[part 1 of 2: package /STELLANTIS/EPT/ASWCs]
AUTOSAR XML (schema 4-2-2)
package /STELLANTIS/EPT/ASWCs
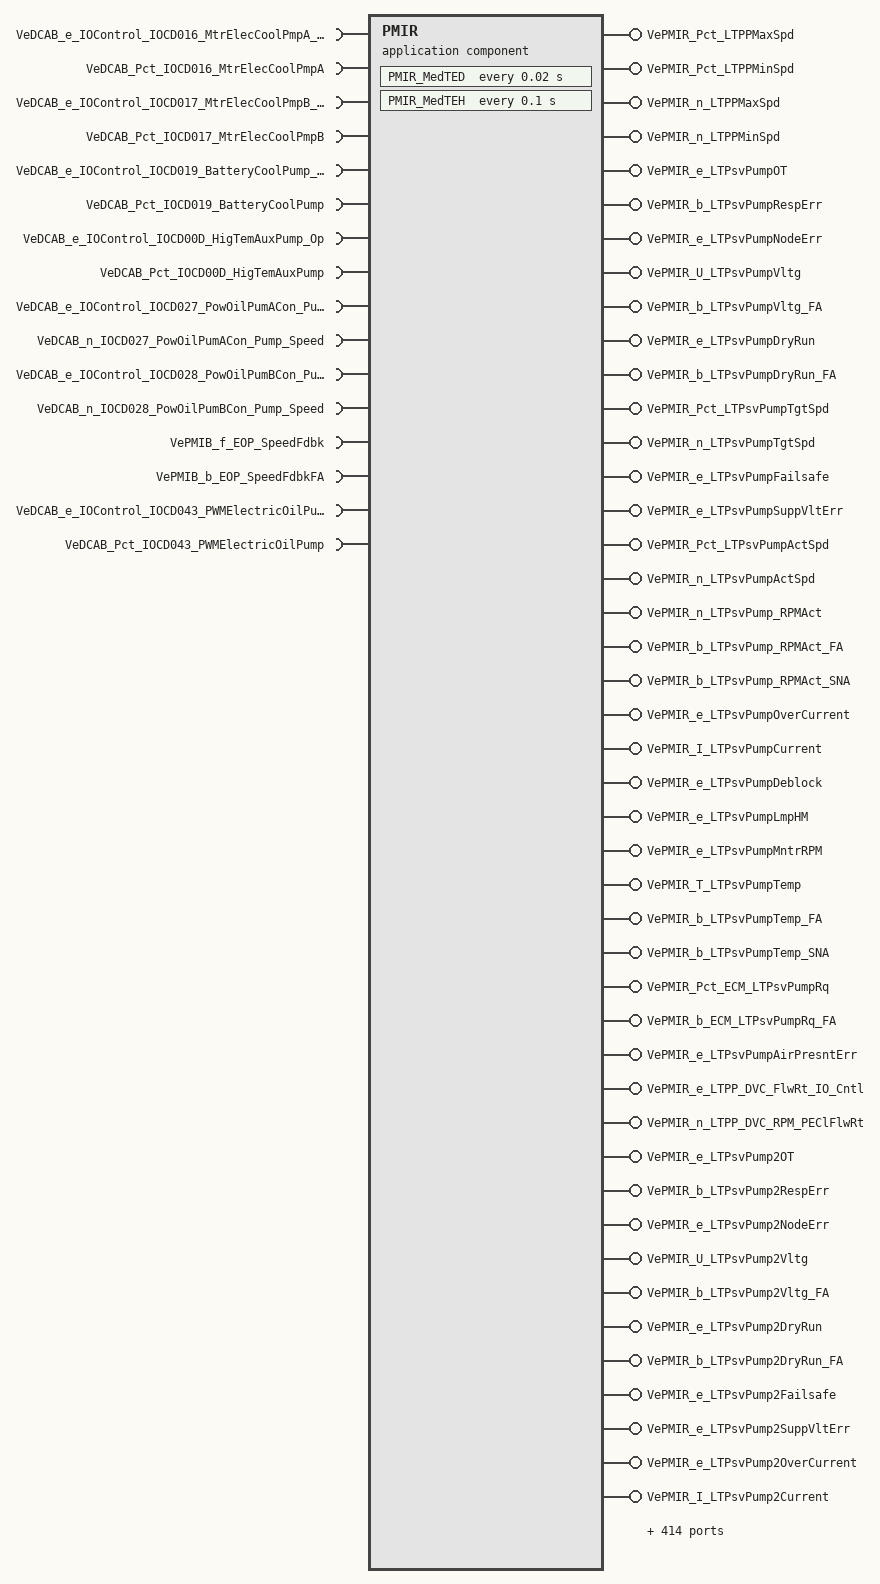
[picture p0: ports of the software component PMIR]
  application sw component type PMIR
    16 x require port:
      VeDCAB_e_IOControl_IOCD016_MtrElecCoolPmpA_Op: nonqueued-receiver-com-spec{data-element=Value, init-value=CeDCAB_e_IO_NOP}, required-interface=VeDCAB_e_IOControl_IOCD016_MtrElecCoolPmpA_Op
      VeDCAB_Pct_IOCD016_MtrElecCoolPmpA: nonqueued-receiver-com-spec{data-element=Value, init-value=0}, required-interface=VeDCAB_Pct_IOCD016_MtrElecCoolPmpA
      VeDCAB_e_IOControl_IOCD017_MtrElecCoolPmpB_Op: nonqueued-receiver-com-spec{data-element=Value, init-value=CeDCAB_e_IO_NOP}, required-interface=VeDCAB_e_IOControl_IOCD017_MtrElecCoolPmpB_Op
      VeDCAB_Pct_IOCD017_MtrElecCoolPmpB: nonqueued-receiver-com-spec{data-element=Value, init-value=0}, required-interface=VeDCAB_Pct_IOCD017_MtrElecCoolPmpB
      VeDCAB_e_IOControl_IOCD019_BatteryCoolPump_Op: nonqueued-receiver-com-spec{data-element=Value, init-value=CeDCAB_e_IO_NOP}, required-interface=VeDCAB_e_IOControl_IOCD019_BatteryCoolPump_Op
      VeDCAB_Pct_IOCD019_BatteryCoolPump: nonqueued-receiver-com-spec{data-element=Value, init-value=0}, required-interface=VeDCAB_Pct_IOCD019_BatteryCoolPump
      VeDCAB_e_IOControl_IOCD00D_HigTemAuxPump_Op: nonqueued-receiver-com-spec{data-element=Value, init-value=CeDCAB_e_IO_NOP}, required-interface=VeDCAB_e_IOControl_IOCD00D_HigTemAuxPump_Op
      VeDCAB_Pct_IOCD00D_HigTemAuxPump: nonqueued-receiver-com-spec{data-element=Value, init-value=0}, required-interface=VeDCAB_Pct_IOCD00D_HigTemAuxPump
      VeDCAB_e_IOControl_IOCD027_PowOilPumACon_Pump_Speed_Op: nonqueued-receiver-com-spec{data-element=Value, init-value=CeDCAB_e_IO_NOP}, required-interface=VeDCAB_e_IOControl_IOCD027_PowOilPumACon_Pump_Speed_Op
      VeDCAB_n_IOCD027_PowOilPumACon_Pump_Speed: nonqueued-receiver-com-spec{data-element=Value, init-value=0}, required-interface=VeDCAB_n_IOCD027_PowOilPumACon_Pump_Speed
      VeDCAB_e_IOControl_IOCD028_PowOilPumBCon_Pump_Speed_Op: nonqueued-receiver-com-spec{data-element=Value, init-value=CeDCAB_e_IO_NOP}, required-interface=VeDCAB_e_IOControl_IOCD028_PowOilPumBCon_Pump_Speed_Op
      VeDCAB_n_IOCD028_PowOilPumBCon_Pump_Speed: nonqueued-receiver-com-spec{data-element=Value, init-value=0}, required-interface=VeDCAB_n_IOCD028_PowOilPumBCon_Pump_Speed
      VePMIB_f_EOP_SpeedFdbk: nonqueued-receiver-com-spec{data-element=Value, init-value=0}, required-interface=VePMIB_f_EOP_SpeedFdbk
      VePMIB_b_EOP_SpeedFdbkFA: nonqueued-receiver-com-spec{data-element=Value, init-value=0}, required-interface=VePMIB_b_EOP_SpeedFdbkFA
      VeDCAB_e_IOControl_IOCD043_PWMElectricOilPump_Op: nonqueued-receiver-com-spec{data-element=Value, init-value=CeDCAB_e_IO_NOP}, required-interface=VeDCAB_e_IOControl_IOCD043_PWMElectricOilPump_Op
      VeDCAB_Pct_IOCD043_PWMElectricOilPump: nonqueued-receiver-com-spec{data-element=Value, init-value=0}, required-interface=VeDCAB_Pct_IOCD043_PWMElectricOilPump
    458 x provide port:
      VePMIR_Pct_LTPPMaxSpd: nonqueued-sender-com-spec{data-element=Value, init-value=0}, provided-interface=VePMIR_Pct_LTPPMaxSpd
      VePMIR_Pct_LTPPMinSpd: nonqueued-sender-com-spec{data-element=Value, init-value=0}, provided-interface=VePMIR_Pct_LTPPMinSpd
      VePMIR_n_LTPPMaxSpd: nonqueued-sender-com-spec{data-element=Value, init-value=0}, provided-interface=VePMIR_n_LTPPMaxSpd
      VePMIR_n_LTPPMinSpd: nonqueued-sender-com-spec{data-element=Value, init-value=0}, provided-interface=VePMIR_n_LTPPMinSpd
      VePMIR_e_LTPsvPumpOT: nonqueued-sender-com-spec{data-element=Value, init-value=CePMPR_e_FTSNA_False}, provided-interface=VePMIR_e_LTPsvPumpOT
      VePMIR_b_LTPsvPumpRespErr: nonqueued-sender-com-spec{data-element=Value, init-value=0}, provided-interface=VePMIR_b_LTPsvPumpRespErr
      VePMIR_e_LTPsvPumpNodeErr: nonqueued-sender-com-spec{data-element=Value, init-value=CePMPR_e_NodeError_NoError}, provided-interface=VePMIR_e_LTPsvPumpNodeErr
      VePMIR_U_LTPsvPumpVltg: nonqueued-sender-com-spec{data-element=Value, init-value=0}, provided-interface=VePMIR_U_LTPsvPumpVltg
      VePMIR_b_LTPsvPumpVltg_FA: nonqueued-sender-com-spec{data-element=Value, init-value=0}, provided-interface=VePMIR_b_LTPsvPumpVltg_FA
      VePMIR_e_LTPsvPumpDryRun: nonqueued-sender-com-spec{data-element=Value, init-value=CePMPR_e_FTSNA_False}, provided-interface=VePMIR_e_LTPsvPumpDryRun
      VePMIR_b_LTPsvPumpDryRun_FA: nonqueued-sender-com-spec{data-element=Value, init-value=0}, provided-interface=VePMIR_b_LTPsvPumpDryRun_FA
      VePMIR_Pct_LTPsvPumpTgtSpd: nonqueued-sender-com-spec{data-element=Value, init-value=0}, provided-interface=VePMIR_Pct_LTPsvPumpTgtSpd
      VePMIR_n_LTPsvPumpTgtSpd: nonqueued-sender-com-spec{data-element=Value, init-value=0}, provided-interface=VePMIR_n_LTPsvPumpTgtSpd
      VePMIR_e_LTPsvPumpFailsafe: nonqueued-sender-com-spec{data-element=Value, init-value=CePMPR_e_TFSNA_False}, provided-interface=VePMIR_e_LTPsvPumpFailsafe
      VePMIR_e_LTPsvPumpSuppVltErr: nonqueued-sender-com-spec{data-element=Value, init-value=CePMPR_e_FTSNA_False}, provided-interface=VePMIR_e_LTPsvPumpSuppVltErr
      VePMIR_Pct_LTPsvPumpActSpd: nonqueued-sender-com-spec{data-element=Value, init-value=0}, provided-interface=VePMIR_Pct_LTPsvPumpActSpd
      VePMIR_n_LTPsvPumpActSpd: nonqueued-sender-com-spec{data-element=Value, init-value=0}, provided-interface=VePMIR_n_LTPsvPumpActSpd
      VePMIR_n_LTPsvPump_RPMAct: nonqueued-sender-com-spec{data-element=Value, init-value=0}, provided-interface=VePMIR_n_LTPsvPump_RPMAct
      VePMIR_b_LTPsvPump_RPMAct_FA: nonqueued-sender-com-spec{data-element=Value, init-value=0}, provided-interface=VePMIR_b_LTPsvPump_RPMAct_FA
      VePMIR_b_LTPsvPump_RPMAct_SNA: nonqueued-sender-com-spec{data-element=Value, init-value=0}, provided-interface=VePMIR_b_LTPsvPump_RPMAct_SNA
      VePMIR_e_LTPsvPumpOverCurrent: nonqueued-sender-com-spec{data-element=Value, init-value=CePMPR_e_FTSNA_False}, provided-interface=VePMIR_e_LTPsvPumpOverCurrent
      VePMIR_I_LTPsvPumpCurrent: nonqueued-sender-com-spec{data-element=Value, init-value=0}, provided-interface=VePMIR_I_LTPsvPumpCurrent
      VePMIR_e_LTPsvPumpDeblock: nonqueued-sender-com-spec{data-element=Value, init-value=CePMPR_e_FTSNA_False}, provided-interface=VePMIR_e_LTPsvPumpDeblock
      VePMIR_e_LTPsvPumpLmpHM: nonqueued-sender-com-spec{data-element=Value, init-value=CePMPR_e_FTSNA_False}, provided-interface=VePMIR_e_LTPsvPumpLmpHM
      VePMIR_e_LTPsvPumpMntrRPM: nonqueued-sender-com-spec{data-element=Value, init-value=CePMPR_e_TFSNA_False}, provided-interface=VePMIR_e_LTPsvPumpMntrRPM
      VePMIR_T_LTPsvPumpTemp: nonqueued-sender-com-spec{data-element=Value, init-value=0}, provided-interface=VePMIR_T_LTPsvPumpTemp
      VePMIR_b_LTPsvPumpTemp_FA: nonqueued-sender-com-spec{data-element=Value, init-value=0}, provided-interface=VePMIR_b_LTPsvPumpTemp_FA
      VePMIR_b_LTPsvPumpTemp_SNA: nonqueued-sender-com-spec{data-element=Value, init-value=0}, provided-interface=VePMIR_b_LTPsvPumpTemp_SNA
      VePMIR_Pct_ECM_LTPsvPumpRq: nonqueued-sender-com-spec{data-element=Value, init-value=0}, provided-interface=VePMIR_Pct_ECM_LTPsvPumpRq
      VePMIR_b_ECM_LTPsvPumpRq_FA: nonqueued-sender-com-spec{data-element=Value, init-value=0}, provided-interface=VePMIR_b_ECM_LTPsvPumpRq_FA
      VePMIR_e_LTPsvPumpAirPresntErr: nonqueued-sender-com-spec{data-element=Value, init-value=CePMPR_e_FTSNA_False}, provided-interface=VePMIR_e_LTPsvPumpAirPresntErr
      VePMIR_e_LTPP_DVC_FlwRt_IO_Cntl: nonqueued-sender-com-spec{data-element=Value, init-value=CeTAIR_e_Return_Control_to_ECU}, provided-interface=VePMIR_e_LTPP_DVC_FlwRt_IO_Cntl
      VePMIR_n_LTPP_DVC_RPM_PEClFlwRt: nonqueued-sender-com-spec{data-element=Value, init-value=0}, provided-interface=VePMIR_n_LTPP_DVC_RPM_PEClFlwRt
      VePMIR_e_LTPsvPump2OT: nonqueued-sender-com-spec{data-element=Value, init-value=CePMPR_e_FTSNA_False}, provided-interface=VePMIR_e_LTPsvPump2OT
      VePMIR_b_LTPsvPump2RespErr: nonqueued-sender-com-spec{data-element=Value, init-value=0}, provided-interface=VePMIR_b_LTPsvPump2RespErr
      VePMIR_e_LTPsvPump2NodeErr: nonqueued-sender-com-spec{data-element=Value, init-value=CePMPR_e_NodeError_NoError}, provided-interface=VePMIR_e_LTPsvPump2NodeErr
      VePMIR_U_LTPsvPump2Vltg: nonqueued-sender-com-spec{data-element=Value, init-value=0}, provided-interface=VePMIR_U_LTPsvPump2Vltg
      VePMIR_b_LTPsvPump2Vltg_FA: nonqueued-sender-com-spec{data-element=Value, init-value=0}, provided-interface=VePMIR_b_LTPsvPump2Vltg_FA
      VePMIR_e_LTPsvPump2DryRun: nonqueued-sender-com-spec{data-element=Value, init-value=CePMPR_e_FTSNA_False}, provided-interface=VePMIR_e_LTPsvPump2DryRun
      VePMIR_b_LTPsvPump2DryRun_FA: nonqueued-sender-com-spec{data-element=Value, init-value=0}, provided-interface=VePMIR_b_LTPsvPump2DryRun_FA
      VePMIR_e_LTPsvPump2Failsafe: nonqueued-sender-com-spec{data-element=Value, init-value=CePMPR_e_TFSNA_False}, provided-interface=VePMIR_e_LTPsvPump2Failsafe
      VePMIR_e_LTPsvPump2SuppVltErr: nonqueued-sender-com-spec{data-element=Value, init-value=CePMPR_e_FTSNA_False}, provided-interface=VePMIR_e_LTPsvPump2SuppVltErr
      VePMIR_e_LTPsvPump2OverCurrent: nonqueued-sender-com-spec{data-element=Value, init-value=CePMPR_e_FTSNA_False}, provided-interface=VePMIR_e_LTPsvPump2OverCurrent
      VePMIR_I_LTPsvPump2Current: nonqueued-sender-com-spec{data-element=Value, init-value=0}, provided-interface=VePMIR_I_LTPsvPump2Current
      VePMIR_e_LTPsvPump2Deblock: nonqueued-sender-com-spec{data-element=Value, init-value=CePMPR_e_FTSNA_False}, provided-interface=VePMIR_e_LTPsvPump2Deblock
      VePMIR_e_LTPsvPump2LmpHM: nonqueued-sender-com-spec{data-element=Value, init-value=CePMPR_e_FTSNA_False}, provided-interface=VePMIR_e_LTPsvPump2LmpHM
      VePMIR_e_LTPsvPump2MntrRPM: nonqueued-sender-com-spec{data-element=Value, init-value=CePMPR_e_TFSNA_False}, provided-interface=VePMIR_e_LTPsvPump2MntrRPM
      VePMIR_T_LTPsvPump2Temp: nonqueued-sender-com-spec{data-element=Value, init-value=0}, provided-interface=VePMIR_T_LTPsvPump2Temp
      VePMIR_b_LTPsvPump2Temp_FA: nonqueued-sender-com-spec{data-element=Value, init-value=0}, provided-interface=VePMIR_b_LTPsvPump2Temp_FA
      VePMIR_b_LTPsvPump2Temp_SNA: nonqueued-sender-com-spec{data-element=Value, init-value=0}, provided-interface=VePMIR_b_LTPsvPump2Temp_SNA
      VePMIR_e_LTPsvPump2AirPresntErr: nonqueued-sender-com-spec{data-element=Value, init-value=CePMPR_e_FTSNA_False}, provided-interface=VePMIR_e_LTPsvPump2AirPresntErr
      VePMIR_Pct_LTPsvPump2TgtSpd: nonqueued-sender-com-spec{data-element=Value, init-value=0}, provided-interface=VePMIR_Pct_LTPsvPump2TgtSpd
      VePMIR_Pct_LTPsvPump2ActSpd: nonqueued-sender-com-spec{data-element=Value, init-value=0}, provided-interface=VePMIR_Pct_LTPsvPump2ActSpd
      VePMIR_n_LTPsvPump2ActSpd: nonqueued-sender-com-spec{data-element=Value, init-value=0}, provided-interface=VePMIR_n_LTPsvPump2ActSpd
      VePMIR_n_LTPsvPump2RPMAct: nonqueued-sender-com-spec{data-element=Value, init-value=0}, provided-interface=VePMIR_n_LTPsvPump2RPMAct
      VePMIR_b_LTPsvPump2RPMAct_FA: nonqueued-sender-com-spec{data-element=Value, init-value=0}, provided-interface=VePMIR_b_LTPsvPump2RPMAct_FA
      VePMIR_b_LTPsvPump2RPMAct_SNA: nonqueued-sender-com-spec{data-element=Value, init-value=0}, provided-interface=VePMIR_b_LTPsvPump2RPMAct_SNA
      VePMIR_e_LTPP2_DVC_FlwRt_IO_Cntl: nonqueued-sender-com-spec{data-element=Value, init-value=CeTAIR_e_Return_Control_to_ECU}, provided-interface=VePMIR_e_LTPP2_DVC_FlwRt_IO_Cntl
      VePMIR_n_LTPP2_DVC_RPM_PEClFlwRt: nonqueued-sender-com-spec{data-element=Value, init-value=0}, provided-interface=VePMIR_n_LTPP2_DVC_RPM_PEClFlwRt
      VePMIR_Pct_LTPP2MaxSpd: nonqueued-sender-com-spec{data-element=Value, init-value=0}, provided-interface=VePMIR_Pct_LTPP2MaxSpd
      VePMIR_Pct_LTPP2MinSpd: nonqueued-sender-com-spec{data-element=Value, init-value=0}, provided-interface=VePMIR_Pct_LTPP2MinSpd
      VePMIR_n_LTPP2MaxSpd: nonqueued-sender-com-spec{data-element=Value, init-value=0}, provided-interface=VePMIR_n_LTPP2MaxSpd
      VePMIR_n_LTPP2MinSpd: nonqueued-sender-com-spec{data-element=Value, init-value=0}, provided-interface=VePMIR_n_LTPP2MinSpd
      VePMIR_e_LTActvPumpOT: nonqueued-sender-com-spec{data-element=Value, init-value=CePMPR_e_FTSNA_False}, provided-interface=VePMIR_e_LTActvPumpOT
      VePMIR_b_LTActvPumpRespErr: nonqueued-sender-com-spec{data-element=Value, init-value=0}, provided-interface=VePMIR_b_LTActvPumpRespErr
      VePMIR_e_LTActvPumpNodeErr: nonqueued-sender-com-spec{data-element=Value, init-value=CePMPR_e_NodeError_NoError}, provided-interface=VePMIR_e_LTActvPumpNodeErr
      VePMIR_U_LTActvPumpVlt: nonqueued-sender-com-spec{data-element=Value, init-value=0}, provided-interface=VePMIR_U_LTActvPumpVlt
      VePMIR_b_LTActvPumpVlt_FA: nonqueued-sender-com-spec{data-element=Value, init-value=0}, provided-interface=VePMIR_b_LTActvPumpVlt_FA
      VePMIR_e_LTActvPumpDryRun: nonqueued-sender-com-spec{data-element=Value, init-value=CePMPR_e_FTSNA_False}, provided-interface=VePMIR_e_LTActvPumpDryRun
      VePMIR_b_LTActvPumpDryRun_FA: nonqueued-sender-com-spec{data-element=Value, init-value=0}, provided-interface=VePMIR_b_LTActvPumpDryRun_FA
      VePMIR_b_LTActvPumpDryRun_SNA: nonqueued-sender-com-spec{data-element=Value, init-value=0}, provided-interface=VePMIR_b_LTActvPumpDryRun_SNA
      VePMIR_e_LTActvPumpFailsafe: nonqueued-sender-com-spec{data-element=Value, init-value=CePMPR_e_TFSNA_False}, provided-interface=VePMIR_e_LTActvPumpFailsafe
      VePMIR_e_LTActvPumpSuppVltErr: nonqueued-sender-com-spec{data-element=Value, init-value=CePMPR_e_FTSNA_False}, provided-interface=VePMIR_e_LTActvPumpSuppVltErr
      VePMIR_e_LTActvPumpOverCurrent: nonqueued-sender-com-spec{data-element=Value, init-value=CePMPR_e_FTSNA_False}, provided-interface=VePMIR_e_LTActvPumpOverCurrent
      VePMIR_I_LTActvPumpCurrent: nonqueued-sender-com-spec{data-element=Value, init-value=0}, provided-interface=VePMIR_I_LTActvPumpCurrent
      VePMIR_e_LTActvPumpDeblock: nonqueued-sender-com-spec{data-element=Value, init-value=CePMPR_e_FTSNA_False}, provided-interface=VePMIR_e_LTActvPumpDeblock
      VePMIR_T_LTActvPumpTemp: nonqueued-sender-com-spec{data-element=Value, init-value=0}, provided-interface=VePMIR_T_LTActvPumpTemp
      VePMIR_b_LTActvPumpTemp_FA: nonqueued-sender-com-spec{data-element=Value, init-value=0}, provided-interface=VePMIR_b_LTActvPumpTemp_FA
      VePMIR_b_LTActvPumpTemp_SNA: nonqueued-sender-com-spec{data-element=Value, init-value=0}, provided-interface=VePMIR_b_LTActvPumpTemp_SNA
      VePMIR_e_LTActvPumpMntrRPM: nonqueued-sender-com-spec{data-element=Value, init-value=CePMPR_e_FTSNA_False}, provided-interface=VePMIR_e_LTActvPumpMntrRPM
      VePMIR_e_LTActvPumpLmpHM: nonqueued-sender-com-spec{data-element=Value, init-value=CePMPR_e_FTSNA_False}, provided-interface=VePMIR_e_LTActvPumpLmpHM
      VePMIR_e_LTActvPumpPstRnSt: nonqueued-sender-com-spec{data-element=Value, init-value=CeTMIR_e_No_AftRunRequest}, provided-interface=VePMIR_e_LTActvPumpPstRnSt
      VePMIR_e_LTAP_AirPrsntErr: nonqueued-sender-com-spec{data-element=Value, init-value=CePMPR_e_FTSNA_False}, provided-interface=VePMIR_e_LTAP_AirPrsntErr
      VePMIR_Pct_LTActvPumpTgtSpd: nonqueued-sender-com-spec{data-element=Value, init-value=0}, provided-interface=VePMIR_Pct_LTActvPumpTgtSpd
      VePMIR_n_LTActvPumpRPMTgt: nonqueued-sender-com-spec{data-element=Value, init-value=0}, provided-interface=VePMIR_n_LTActvPumpRPMTgt
      VePMIR_Pct_LTActvPumpActSpd: nonqueued-sender-com-spec{data-element=Value, init-value=0}, provided-interface=VePMIR_Pct_LTActvPumpActSpd
      VePMIR_n_LTActvPumpRPMAct: nonqueued-sender-com-spec{data-element=Value, init-value=0}, provided-interface=VePMIR_n_LTActvPumpRPMAct
      VePMIR_b_LTActvPumpRPMAct_FA: nonqueued-sender-com-spec{data-element=Value, init-value=0}, provided-interface=VePMIR_b_LTActvPumpRPMAct_FA
      VePMIR_b_LTActvPumpRPMAct_SNA: nonqueued-sender-com-spec{data-element=Value, init-value=0}, provided-interface=VePMIR_b_LTActvPumpRPMAct_SNA
      VePMIR_e_LTAP_DVC_FlwRt_IO_Cntl: nonqueued-sender-com-spec{data-element=Value, init-value=CeTAIR_e_Return_Control_to_ECU}, provided-interface=VePMIR_e_LTAP_DVC_FlwRt_IO_Cntl
      VePMIR_n_LTAP_DVC_RPM_PEClFlwRt: nonqueued-sender-com-spec{data-element=Value, init-value=0}, provided-interface=VePMIR_n_LTAP_DVC_RPM_PEClFlwRt
      VePMIR_e_HTAuxPumpOT: nonqueued-sender-com-spec{data-element=Value, init-value=CePMPR_e_FTSNA_False}, provided-interface=VePMIR_e_HTAuxPumpOT
      VePMIR_b_HTAuxPumpRespErr: nonqueued-sender-com-spec{data-element=Value, init-value=0}, provided-interface=VePMIR_b_HTAuxPumpRespErr
      VePMIR_e_HTAuxPumpNodeErr: nonqueued-sender-com-spec{data-element=Value, init-value=CePMPR_e_NodeError_NoError}, provided-interface=VePMIR_e_HTAuxPumpNodeErr
      VePMIR_U_HTAuxPumpVltg: nonqueued-sender-com-spec{data-element=Value, init-value=0}, provided-interface=VePMIR_U_HTAuxPumpVltg
      VePMIR_b_HTAuxPumpVltg_FA: nonqueued-sender-com-spec{data-element=Value, init-value=0}, provided-interface=VePMIR_b_HTAuxPumpVltg_FA
      VePMIR_e_HTAuxPumpDryRun: nonqueued-sender-com-spec{data-element=Value, init-value=CePMPR_e_FTSNA_False}, provided-interface=VePMIR_e_HTAuxPumpDryRun
      VePMIR_b_HTAuxPumpDryRun_FA: nonqueued-sender-com-spec{data-element=Value, init-value=0}, provided-interface=VePMIR_b_HTAuxPumpDryRun_FA
      VePMIR_e_HTAuxPumpFailsafe: nonqueued-sender-com-spec{data-element=Value, init-value=CePMPR_e_TFSNA_False}, provided-interface=VePMIR_e_HTAuxPumpFailsafe
      VePMIR_e_HTAuxPumpSuppVltErr: nonqueued-sender-com-spec{data-element=Value, init-value=CePMPR_e_FTSNA_False}, provided-interface=VePMIR_e_HTAuxPumpSuppVltErr
      VePMIR_e_HTAuxPumpOverCurrent: nonqueued-sender-com-spec{data-element=Value, init-value=CePMPR_e_FTSNA_False}, provided-interface=VePMIR_e_HTAuxPumpOverCurrent
      VePMIR_I_HTAuxPumpCurrent: nonqueued-sender-com-spec{data-element=Value, init-value=0}, provided-interface=VePMIR_I_HTAuxPumpCurrent
      VePMIR_e_HTAuxPumpDeblock: nonqueued-sender-com-spec{data-element=Value, init-value=CePMPR_e_FTSNA_False}, provided-interface=VePMIR_e_HTAuxPumpDeblock
      VePMIR_e_HTAuxPumpMntrRPM: nonqueued-sender-com-spec{data-element=Value, init-value=CePMPR_e_TFSNA_False}, provided-interface=VePMIR_e_HTAuxPumpMntrRPM
      VePMIR_b_HTAuxPumpMntrRPM_FA: nonqueued-sender-com-spec{data-element=Value, init-value=0}, provided-interface=VePMIR_b_HTAuxPumpMntrRPM_FA
      VePMIR_e_HTAuxPumpLmpHM: nonqueued-sender-com-spec{data-element=Value, init-value=CePMPR_e_FTSNA_False}, provided-interface=VePMIR_e_HTAuxPumpLmpHM
      VePMIR_e_HTAuxPumpPstRnSt: nonqueued-sender-com-spec{data-element=Value, init-value=CeTMIR_e_No_AftRunRequest}, provided-interface=VePMIR_e_HTAuxPumpPstRnSt
      VePMIR_T_HTAuxPumpTemp: nonqueued-sender-com-spec{data-element=Value, init-value=0}, provided-interface=VePMIR_T_HTAuxPumpTemp
      VePMIR_b_HTAuxPumpTemp_FA: nonqueued-sender-com-spec{data-element=Value, init-value=0}, provided-interface=VePMIR_b_HTAuxPumpTemp_FA
      VePMIR_b_HTAuxPumpTemp_SNA: nonqueued-sender-com-spec{data-element=Value, init-value=0}, provided-interface=VePMIR_b_HTAuxPumpTemp_SNA
      VePMIR_e_HTAuxPumpAirPresntErr: nonqueued-sender-com-spec{data-element=Value, init-value=CePMPR_e_FTSNA_False}, provided-interface=VePMIR_e_HTAuxPumpAirPresntErr
      VePMIR_Pct_HTAuxPumpTgtSpd: nonqueued-sender-com-spec{data-element=Value, init-value=0}, provided-interface=VePMIR_Pct_HTAuxPumpTgtSpd
      VePMIR_n_HTAuxPumpRPMTgt: nonqueued-sender-com-spec{data-element=Value, init-value=0}, provided-interface=VePMIR_n_HTAuxPumpRPMTgt
      VePMIR_Pct_HTAuxPumpActSpd: nonqueued-sender-com-spec{data-element=Value, init-value=0}, provided-interface=VePMIR_Pct_HTAuxPumpActSpd
      VePMIR_n_HTAuxPumpRPMAct: nonqueued-sender-com-spec{data-element=Value, init-value=0}, provided-interface=VePMIR_n_HTAuxPumpRPMAct
      VePMIR_b_HTAuxPumpRPMAct_FA: nonqueued-sender-com-spec{data-element=Value, init-value=0}, provided-interface=VePMIR_b_HTAuxPumpRPMAct_FA
      VePMIR_b_HTAuxPumpRPMAct_SNA: nonqueued-sender-com-spec{data-element=Value, init-value=0}, provided-interface=VePMIR_b_HTAuxPumpRPMAct_SNA
      VePMIR_e_HTAP_DVC_FlwRt_IO_Cntl: nonqueued-sender-com-spec{data-element=Value, init-value=CeTAIR_e_Return_Control_to_ECU}, provided-interface=VePMIR_e_HTAP_DVC_FlwRt_IO_Cntl
      VePMIR_n_HTAP_DVC_RPM_PEClFlwRt: nonqueued-sender-com-spec{data-element=Value, init-value=0}, provided-interface=VePMIR_n_HTAP_DVC_RPM_PEClFlwRt
      VePMIR_Pct_HTAPMaxSpd: nonqueued-sender-com-spec{data-element=Value, init-value=0}, provided-interface=VePMIR_Pct_HTAPMaxSpd
      VePMIR_Pct_HTAPMinSpd: nonqueued-sender-com-spec{data-element=Value, init-value=0}, provided-interface=VePMIR_Pct_HTAPMinSpd
      VePMIR_n_HTAPMaxSpd: nonqueued-sender-com-spec{data-element=Value, init-value=0}, provided-interface=VePMIR_n_HTAPMaxSpd
      VePMIR_n_HTAPMinSpd: nonqueued-sender-com-spec{data-element=Value, init-value=0}, provided-interface=VePMIR_n_HTAPMinSpd
      VePMIR_n_FCCPmpActSpd: nonqueued-sender-com-spec{data-element=Value, init-value=0}, provided-interface=VePMIR_n_FCCPmpActSpd
      VePMIR_b_FCCPmpActSpd_FA: nonqueued-sender-com-spec{data-element=Value, init-value=0}, provided-interface=VePMIR_b_FCCPmpActSpd_FA
      VePMIR_I_FCCPmpSuppCrnt: nonqueued-sender-com-spec{data-element=Value, init-value=0}, provided-interface=VePMIR_I_FCCPmpSuppCrnt
      VePMIR_T_FCCPmpActTemp: nonqueued-sender-com-spec{data-element=Value, init-value=0}, provided-interface=VePMIR_T_FCCPmpActTemp
      VePMIR_b_FCCPmpActTemp_FA: nonqueued-sender-com-spec{data-element=Value, init-value=0}, provided-interface=VePMIR_b_FCCPmpActTemp_FA
      VePMIR_U_FCCPmpActVlt: nonqueued-sender-com-spec{data-element=Value, init-value=0}, provided-interface=VePMIR_U_FCCPmpActVlt
      VePMIR_b_FCCPmpActVlt_FA: nonqueued-sender-com-spec{data-element=Value, init-value=0}, provided-interface=VePMIR_b_FCCPmpActVlt_FA
      VePMIR_b_FCCPmpErrSC: nonqueued-sender-com-spec{data-element=Value, init-value=0}, provided-interface=VePMIR_b_FCCPmpErrSC
      VePMIR_b_FCCPmpIntFlt: nonqueued-sender-com-spec{data-element=Value, init-value=0}, provided-interface=VePMIR_b_FCCPmpIntFlt
      VePMIR_b_FCCPmpErrLIN: nonqueued-sender-com-spec{data-element=Value, init-value=0}, provided-interface=VePMIR_b_FCCPmpErrLIN
      VePMIR_b_FCCPmpErrLLO: nonqueued-sender-com-spec{data-element=Value, init-value=0}, provided-interface=VePMIR_b_FCCPmpErrLLO
      VePMIR_b_FCCPmpErrOC: nonqueued-sender-com-spec{data-element=Value, init-value=0}, provided-interface=VePMIR_b_FCCPmpErrOC
      VePMIR_b_FCCPmpErrOT: nonqueued-sender-com-spec{data-element=Value, init-value=0}, provided-interface=VePMIR_b_FCCPmpErrOT
      VePMIR_b_FCCPmpErrOTD: nonqueued-sender-com-spec{data-element=Value, init-value=0}, provided-interface=VePMIR_b_FCCPmpErrOTD
      VePMIR_b_FCCPmpErrOV: nonqueued-sender-com-spec{data-element=Value, init-value=0}, provided-interface=VePMIR_b_FCCPmpErrOV
      VePMIR_b_FCCPmpStlFlt: nonqueued-sender-com-spec{data-element=Value, init-value=0}, provided-interface=VePMIR_b_FCCPmpStlFlt
      VePMIR_b_FCCPmpErrUV: nonqueued-sender-com-spec{data-element=Value, init-value=0}, provided-interface=VePMIR_b_FCCPmpErrUV
      VePMIR_b_FCCPmpErrVD: nonqueued-sender-com-spec{data-element=Value, init-value=0}, provided-interface=VePMIR_b_FCCPmpErrVD
      VePMIR_n_AuxPumpSpdAct: nonqueued-sender-com-spec{data-element=Value, init-value=0}, provided-interface=VePMIR_n_AuxPumpSpdAct
      VePMIR_b_AuxPumpSpdAct_FA: nonqueued-sender-com-spec{data-element=Value, init-value=0}, provided-interface=VePMIR_b_AuxPumpSpdAct_FA
      VePMIR_b_AuxPumpSpdAct_SNA: nonqueued-sender-com-spec{data-element=Value, init-value=0}, provided-interface=VePMIR_b_AuxPumpSpdAct_SNA
      VePMIR_T_TransAuxPumpTemp: nonqueued-sender-com-spec{data-element=Value, init-value=0}, provided-interface=VePMIR_T_TransAuxPumpTemp
      VePMIR_b_TransAuxPumpTemp_FA: nonqueued-sender-com-spec{data-element=Value, init-value=0}, provided-interface=VePMIR_b_TransAuxPumpTemp_FA
      VePMIR_I_TransAuxPumpCurrent: nonqueued-sender-com-spec{data-element=Value, init-value=0}, provided-interface=VePMIR_I_TransAuxPumpCurrent
      VePMIR_U_TransAuxPumpVoltage: nonqueued-sender-com-spec{data-element=Value, init-value=0}, provided-interface=VePMIR_U_TransAuxPumpVoltage
      VePMIR_b_TransAuxPumpRespError: nonqueued-sender-com-spec{data-element=Value, init-value=0}, provided-interface=VePMIR_b_TransAuxPumpRespError
      VePMIR_n_TransAuxPump_RPMTgt: nonqueued-sender-com-spec{data-element=Value, init-value=0}, provided-interface=VePMIR_n_TransAuxPump_RPMTgt
      VePMIR_y_TransAuxPmp_TAP_HW_VER: nonqueued-sender-com-spec{data-element=Value, init-value=0}, provided-interface=VePMIR_y_TransAuxPmp_TAP_HW_VER
      VePMIR_y_TransAuxPmp_TAP_SW_VER: nonqueued-sender-com-spec{data-element=Value, init-value=0}, provided-interface=VePMIR_y_TransAuxPmp_TAP_SW_VER
      VePMIR_T_TransAuxPumpOilTemp: nonqueued-sender-com-spec{data-element=Value, init-value=0}, provided-interface=VePMIR_T_TransAuxPumpOilTemp
      VePMIR_b_TransAuxPumpOilTemp_FA: nonqueued-sender-com-spec{data-element=Value, init-value=0}, provided-interface=VePMIR_b_TransAuxPumpOilTemp_FA
      VePMIR_e_TransAuxPumpPstRnSt: nonqueued-sender-com-spec{data-element=Value, init-value=CeTAPR_e_TAP_PostRunCmd_NoPostRun}, provided-interface=VePMIR_e_TransAuxPumpPstRnSt
      VePMIR_e_TransAuxPumpLmpHM: nonqueued-sender-com-spec{data-element=Value, init-value=CeTAPR_e_TAP_FalseTrueSNA_False}, provided-interface=VePMIR_e_TransAuxPumpLmpHM
      VePMIR_e_TransAuxPumpDryRun: nonqueued-sender-com-spec{data-element=Value, init-value=CeTAPR_e_TAP_FalseTrueSNA_False}, provided-interface=VePMIR_e_TransAuxPumpDryRun
      VePMIR_b_TransAuxPumpDryRun_FA: nonqueued-sender-com-spec{data-element=Value, init-value=0}, provided-interface=VePMIR_b_TransAuxPumpDryRun_FA
      VePMIR_e_TAP_ColdBiasSts: nonqueued-sender-com-spec{data-element=Value, init-value=CeTAPR_e_TAP_FalseTrueSNA_False}, provided-interface=VePMIR_e_TAP_ColdBiasSts
      VePMIR_e_TransAuxPumpMntrRPM: nonqueued-sender-com-spec{data-element=Value, init-value=CeTAPR_e_TAP_TrueFalseSNA_False}, provided-interface=VePMIR_e_TransAuxPumpMntrRPM
      VePMIR_e_TransAuxPumpTempError: nonqueued-sender-com-spec{data-element=Value, init-value=CeTAPR_e_TmpErr_NO_FAULT}, provided-interface=VePMIR_e_TransAuxPumpTempError
      VePMIR_e_TransAuxPumpCurrentError: nonqueued-sender-com-spec{data-element=Value, init-value=CeTAPR_e_CrntErr_NO_FAULT}, provided-interface=VePMIR_e_TransAuxPumpCurrentError
      VePMIR_e_TransAuxPumpStallEvent: nonqueued-sender-com-spec{data-element=Value, init-value=CeTAPR_e_StallEvnt_FALSE}, provided-interface=VePMIR_e_TransAuxPumpStallEvent
      VePMIR_e_TransAuxPumpVoltageError: nonqueued-sender-com-spec{data-element=Value, init-value=CeTAPR_e_VltgtErr_NO_FAULT}, provided-interface=VePMIR_e_TransAuxPumpVoltageError
      VePMIR_b_TransAuxPumpTCMReq: nonqueued-sender-com-spec{data-element=Value, init-value=0}, provided-interface=VePMIR_b_TransAuxPumpTCMReq
      VePMIR_e_TAP_SpdDsrd_IO_CntrlSt: nonqueued-sender-com-spec{data-element=Value, init-value=CeTAIR_e_Return_Control_to_ECU}, provided-interface=VePMIR_e_TAP_SpdDsrd_IO_CntrlSt
      VePMIR_n_DVC_AuxPumpSpdDsrd: nonqueued-sender-com-spec{data-element=Value, init-value=0}, provided-interface=VePMIR_n_DVC_AuxPumpSpdDsrd
      VePMIR_n_EOP_SpeedFdbk: nonqueued-sender-com-spec{data-element=Value, init-value=0}, provided-interface=VePMIR_n_EOP_SpeedFdbk
      VePMIR_b_EOP_SpeedFdbk_FA: nonqueued-sender-com-spec{data-element=Value, init-value=0}, provided-interface=VePMIR_b_EOP_SpeedFdbk_FA
      VePMIR_b_PWM_TAP_Sel: nonqueued-sender-com-spec{data-element=Value, init-value=0}, provided-interface=VePMIR_b_PWM_TAP_Sel
      VePMIR_n_TransAuxPump2SpdAct: nonqueued-sender-com-spec{data-element=Value, init-value=0}, provided-interface=VePMIR_n_TransAuxPump2SpdAct
      VePMIR_b_TransAuxPump2SpdAct_FA: nonqueued-sender-com-spec{data-element=Value, init-value=0}, provided-interface=VePMIR_b_TransAuxPump2SpdAct_FA
      VePMIR_b_TransAuxPump2SpdAct_SNA: nonqueued-sender-com-spec{data-element=Value, init-value=0}, provided-interface=VePMIR_b_TransAuxPump2SpdAct_SNA
      VePMIR_T_TransAuxPump2Temp: nonqueued-sender-com-spec{data-element=Value, init-value=0}, provided-interface=VePMIR_T_TransAuxPump2Temp
      VePMIR_b_TransAuxPump2Temp_FA: nonqueued-sender-com-spec{data-element=Value, init-value=0}, provided-interface=VePMIR_b_TransAuxPump2Temp_FA
      VePMIR_I_TransAuxPump2Current: nonqueued-sender-com-spec{data-element=Value, init-value=0}, provided-interface=VePMIR_I_TransAuxPump2Current
      VePMIR_b_TransAuxPump2Current_FA: nonqueued-sender-com-spec{data-element=Value, init-value=0}, provided-interface=VePMIR_b_TransAuxPump2Current_FA
      VePMIR_U_TransAuxPump2Voltage: nonqueued-sender-com-spec{data-element=Value, init-value=0}, provided-interface=VePMIR_U_TransAuxPump2Voltage
      VePMIR_b_TransAuxPump2Voltage_FA: nonqueued-sender-com-spec{data-element=Value, init-value=0}, provided-interface=VePMIR_b_TransAuxPump2Voltage_FA
      VePMIR_b_TransAuxPump2RespError: nonqueued-sender-com-spec{data-element=Value, init-value=0}, provided-interface=VePMIR_b_TransAuxPump2RespError
      VePMIR_n_TransAuxPump2TgtSpd: nonqueued-sender-com-spec{data-element=Value, init-value=0}, provided-interface=VePMIR_n_TransAuxPump2TgtSpd
      VePMIR_b_TransAuxPump2TgtSpd_FA: nonqueued-sender-com-spec{data-element=Value, init-value=0}, provided-interface=VePMIR_b_TransAuxPump2TgtSpd_FA
      VePMIR_y_TransAuxPmp2_TAP_HW_VER: nonqueued-sender-com-spec{data-element=Value, init-value=0}, provided-interface=VePMIR_y_TransAuxPmp2_TAP_HW_VER
      VePMIR_y_TransAuxPmp2_TAP_SW_VER: nonqueued-sender-com-spec{data-element=Value, init-value=0}, provided-interface=VePMIR_y_TransAuxPmp2_TAP_SW_VER
      VePMIR_T_TransAuxPump2OilTemp: nonqueued-sender-com-spec{data-element=Value, init-value=0}, provided-interface=VePMIR_T_TransAuxPump2OilTemp
      VePMIR_b_TransAuxPump2OilTemp_FA: nonqueued-sender-com-spec{data-element=Value, init-value=0}, provided-interface=VePMIR_b_TransAuxPump2OilTemp_FA
      VePMIR_e_TransAuxPump2PstRnSt: nonqueued-sender-com-spec{data-element=Value, init-value=CeTAPR_e_TAP_PostRunCmd_NoPostRun}, provided-interface=VePMIR_e_TransAuxPump2PstRnSt
      VePMIR_b_TransAuxPump2PstRnSt_FA: nonqueued-sender-com-spec{data-element=Value, init-value=0}, provided-interface=VePMIR_b_TransAuxPump2PstRnSt_FA
      VePMIR_e_TransAuxPmp2LmpHM: nonqueued-sender-com-spec{data-element=Value, init-value=CeTAPR_e_TAP_FalseTrueSNA_False}, provided-interface=VePMIR_e_TransAuxPmp2LmpHM
      VePMIR_b_TransAuxPmp2LmpHM_FA: nonqueued-sender-com-spec{data-element=Value, init-value=0}, provided-interface=VePMIR_b_TransAuxPmp2LmpHM_FA
      VePMIR_e_TransAuxPump2DryRun: nonqueued-sender-com-spec{data-element=Value, init-value=CeTAPR_e_TAP_FalseTrueSNA_False}, provided-interface=VePMIR_e_TransAuxPump2DryRun
      VePMIR_b_TransAuxPump2DryRun_FA: nonqueued-sender-com-spec{data-element=Value, init-value=0}, provided-interface=VePMIR_b_TransAuxPump2DryRun_FA
      VePMIR_e_TransAuxPmp2ColdBiasSts: nonqueued-sender-com-spec{data-element=Value, init-value=CeTAPR_e_TAP_FalseTrueSNA_False}, provided-interface=VePMIR_e_TransAuxPmp2ColdBiasSts
      VePMIR_b_TransAuxPmp2ColdBiasSts_FA: nonqueued-sender-com-spec{data-element=Value, init-value=0}, provided-interface=VePMIR_b_TransAuxPmp2ColdBiasSts_FA
      VePMIR_e_TransAuxPump2MntrRPM: nonqueued-sender-com-spec{data-element=Value, init-value=CeTAPR_e_TAP_FalseTrueSNA_False}, provided-interface=VePMIR_e_TransAuxPump2MntrRPM
      VePMIR_b_TransAuxPump2MntrRPM_FA: nonqueued-sender-com-spec{data-element=Value, init-value=0}, provided-interface=VePMIR_b_TransAuxPump2MntrRPM_FA
      VePMIR_e_TransAuxPump2TempError: nonqueued-sender-com-spec{data-element=Value, init-value=CeTAPR_e_TmpErr_NO_FAULT}, provided-interface=VePMIR_e_TransAuxPump2TempError
      VePMIR_b_TransAuxPump2TempError_FA: nonqueued-sender-com-spec{data-element=Value, init-value=0}, provided-interface=VePMIR_b_TransAuxPump2TempError_FA
      VePMIR_e_TransAuxPump2CurrentError: nonqueued-sender-com-spec{data-element=Value, init-value=CeTAPR_e_CrntErr_NO_FAULT}, provided-interface=VePMIR_e_TransAuxPump2CurrentError
      VePMIR_b_TransAuxPump2CurrentError_FA: nonqueued-sender-com-spec{data-element=Value, init-value=0}, provided-interface=VePMIR_b_TransAuxPump2CurrentError_FA
      VePMIR_e_TransAuxPump2StallEvent: nonqueued-sender-com-spec{data-element=Value, init-value=CeTAPR_e_StallEvnt_FALSE}, provided-interface=VePMIR_e_TransAuxPump2StallEvent
      VePMIR_b_TransAuxPump2StallEvent_FA: nonqueued-sender-com-spec{data-element=Value, init-value=0}, provided-interface=VePMIR_b_TransAuxPump2StallEvent_FA
      VePMIR_e_TransAuxPump2VoltageError: nonqueued-sender-com-spec{data-element=Value, init-value=CeTAPR_e_VltgtErr_NO_FAULT}, provided-interface=VePMIR_e_TransAuxPump2VoltageError
      VePMIR_b_TransAuxPump2VoltageError_FA: nonqueued-sender-com-spec{data-element=Value, init-value=0}, provided-interface=VePMIR_b_TransAuxPump2VoltageError_FA
      VePMIR_e_TAP2_SpdDsrd_IO_CntrlSt: nonqueued-sender-com-spec{data-element=Value, init-value=CeTAIR_e_Return_Control_to_ECU}, provided-interface=VePMIR_e_TAP2_SpdDsrd_IO_CntrlSt
      VePMIR_n_DVC_AuxPump2SpdDsrd: nonqueued-sender-com-spec{data-element=Value, init-value=0}, provided-interface=VePMIR_n_DVC_AuxPump2SpdDsrd
      VePMIR_e_PWM_EOP_IOCtrlMode: nonqueued-sender-com-spec{data-element=Value, init-value=CeTAIR_e_Return_Control_to_ECU}, provided-interface=VePMIR_e_PWM_EOP_IOCtrlMode
      VePMIR_Pct_PWM_EOP_IOCtrlSpd: nonqueued-sender-com-spec{data-element=Value, init-value=0}, provided-interface=VePMIR_Pct_PWM_EOP_IOCtrlSpd
      VePMIR_b_LTPsvPump2_PstRnStFA: nonqueued-sender-com-spec{data-element=Value, init-value=0}, provided-interface=VePMIR_b_LTPsvPump2_PstRnStFA
      VePMIR_e_LTPsvPump2_PstRnSt: nonqueued-sender-com-spec{data-element=Value, init-value=CeTMIR_e_No_AftRunRequest}, provided-interface=VePMIR_e_LTPsvPump2_PstRnSt
      VePMIR_b_LTPsvPump_PstRnStFA: nonqueued-sender-com-spec{data-element=Value, init-value=0}, provided-interface=VePMIR_b_LTPsvPump_PstRnStFA
      VePMIR_e_LTPsvPump_PstRnSt: nonqueued-sender-com-spec{data-element=Value, init-value=CeTMIR_e_No_AftRunRequest}, provided-interface=VePMIR_e_LTPsvPump_PstRnSt
      FsftPMIR_b_ECM_LTPsvPmpRq: server-com-spec=FsftPMIR_b_ECM_LTPsvPmpRq, provided-interface=FsftPMIR_b_ECM_LTPsvPmpRq
      FsftPMIR_b_FCCPmpActSpd: server-com-spec=FsftPMIR_b_FCCPmpActSpd, provided-interface=FsftPMIR_b_FCCPmpActSpd
      FsftPMIR_b_FCCPmpActTemp: server-com-spec=FsftPMIR_b_FCCPmpActTemp, provided-interface=FsftPMIR_b_FCCPmpActTemp
      FsftPMIR_b_FCCPmpActVlt: server-com-spec=FsftPMIR_b_FCCPmpActVlt, provided-interface=FsftPMIR_b_FCCPmpActVlt
      FsftPMIR_b_HTAuxPmpAirPrsntErr: server-com-spec=FsftPMIR_b_HTAuxPmpAirPrsntErr, provided-interface=FsftPMIR_b_HTAuxPmpAirPrsntErr
      FsftPMIR_b_HTAuxPumpDeblock: server-com-spec=FsftPMIR_b_HTAuxPumpDeblock, provided-interface=FsftPMIR_b_HTAuxPumpDeblock
      FsftPMIR_b_HTAuxPumpDryRun: server-com-spec=FsftPMIR_b_HTAuxPumpDryRun, provided-interface=FsftPMIR_b_HTAuxPumpDryRun
      FsftPMIR_b_HTAuxPumpFailsafe: server-com-spec=FsftPMIR_b_HTAuxPumpFailsafe, provided-interface=FsftPMIR_b_HTAuxPumpFailsafe
      FsftPMIR_b_HTAuxPumpNodeErr: server-com-spec=FsftPMIR_b_HTAuxPumpNodeErr, provided-interface=FsftPMIR_b_HTAuxPumpNodeErr
      FsftPMIR_b_HTAuxPumpOvrCrnt: server-com-spec=FsftPMIR_b_HTAuxPumpOvrCrnt, provided-interface=FsftPMIR_b_HTAuxPumpOvrCrnt
      FsftPMIR_b_HTAuxPumpRPMAct: server-com-spec=FsftPMIR_b_HTAuxPumpRPMAct, provided-interface=FsftPMIR_b_HTAuxPumpRPMAct
      FsftPMIR_b_HTAuxPumpRPMActPct: server-com-spec=FsftPMIR_b_HTAuxPumpRPMActPct, provided-interface=FsftPMIR_b_HTAuxPumpRPMActPct
      FsftPMIR_b_HTAuxPumpRPMTgt: server-com-spec=FsftPMIR_b_HTAuxPumpRPMTgt, provided-interface=FsftPMIR_b_HTAuxPumpRPMTgt
      FsftPMIR_b_HTAuxPumpRPMTgtPct: server-com-spec=FsftPMIR_b_HTAuxPumpRPMTgtPct, provided-interface=FsftPMIR_b_HTAuxPumpRPMTgtPct
      FsftPMIR_b_HTAuxPumpSuppVltErr: server-com-spec=FsftPMIR_b_HTAuxPumpSuppVltErr, provided-interface=FsftPMIR_b_HTAuxPumpSuppVltErr
      FsftPMIR_b_HTAuxPump_LmpHM: server-com-spec=FsftPMIR_b_HTAuxPump_LmpHM, provided-interface=FsftPMIR_b_HTAuxPump_LmpHM
      FsftPMIR_b_HT_AuxPmpCrnt: server-com-spec=FsftPMIR_b_HT_AuxPmpCrnt, provided-interface=FsftPMIR_b_HT_AuxPmpCrnt
      FsftPMIR_b_HT_AuxPmpMntrRPM: server-com-spec=FsftPMIR_b_HT_AuxPmpMntrRPM, provided-interface=FsftPMIR_b_HT_AuxPmpMntrRPM
      FsftPMIR_b_HT_AuxPmpOT: server-com-spec=FsftPMIR_b_HT_AuxPmpOT, provided-interface=FsftPMIR_b_HT_AuxPmpOT
      FsftPMIR_b_HT_AuxPmpTemp: server-com-spec=FsftPMIR_b_HT_AuxPmpTemp, provided-interface=FsftPMIR_b_HT_AuxPmpTemp
      FsftPMIR_b_HT_AuxPmpVltg: server-com-spec=FsftPMIR_b_HT_AuxPmpVltg, provided-interface=FsftPMIR_b_HT_AuxPmpVltg
      FsftPMIR_b_HT_AuxPmp_PstRnSt: server-com-spec=FsftPMIR_b_HT_AuxPmp_PstRnSt, provided-interface=FsftPMIR_b_HT_AuxPmp_PstRnSt
      FsftPMIR_b_LTActPumpAirPrsntErr: server-com-spec=FsftPMIR_b_LTActPumpAirPrsntErr, provided-interface=FsftPMIR_b_LTActPumpAirPrsntErr
      FsftPMIR_b_LTActPumpCrnt: server-com-spec=FsftPMIR_b_LTActPumpCrnt, provided-interface=FsftPMIR_b_LTActPumpCrnt
      FsftPMIR_b_LTActPumpDeblock: server-com-spec=FsftPMIR_b_LTActPumpDeblock, provided-interface=FsftPMIR_b_LTActPumpDeblock
      FsftPMIR_b_LTActPumpDryRun: server-com-spec=FsftPMIR_b_LTActPumpDryRun, provided-interface=FsftPMIR_b_LTActPumpDryRun
      FsftPMIR_b_LTActPumpFailsafe: server-com-spec=FsftPMIR_b_LTActPumpFailsafe, provided-interface=FsftPMIR_b_LTActPumpFailsafe
      FsftPMIR_b_LTActPumpLmpHM: server-com-spec=FsftPMIR_b_LTActPumpLmpHM, provided-interface=FsftPMIR_b_LTActPumpLmpHM
      FsftPMIR_b_LTActPumpMntrRPM: server-com-spec=FsftPMIR_b_LTActPumpMntrRPM, provided-interface=FsftPMIR_b_LTActPumpMntrRPM
      FsftPMIR_b_LTActPumpNodeErr: server-com-spec=FsftPMIR_b_LTActPumpNodeErr, provided-interface=FsftPMIR_b_LTActPumpNodeErr
      FsftPMIR_b_LTActPumpOvrCrnt: server-com-spec=FsftPMIR_b_LTActPumpOvrCrnt, provided-interface=FsftPMIR_b_LTActPumpOvrCrnt
      FsftPMIR_b_LTActPumpPstRnSt: server-com-spec=FsftPMIR_b_LTActPumpPstRnSt, provided-interface=FsftPMIR_b_LTActPumpPstRnSt
      FsftPMIR_b_LTActPumpRPMAct: server-com-spec=FsftPMIR_b_LTActPumpRPMAct, provided-interface=FsftPMIR_b_LTActPumpRPMAct
      FsftPMIR_b_LTActPumpRPMActPct: server-com-spec=FsftPMIR_b_LTActPumpRPMActPct, provided-interface=FsftPMIR_b_LTActPumpRPMActPct
      FsftPMIR_b_LTActPumpRPMTgt: server-com-spec=FsftPMIR_b_LTActPumpRPMTgt, provided-interface=FsftPMIR_b_LTActPumpRPMTgt
      FsftPMIR_b_LTActPumpRPMTgtPct: server-com-spec=FsftPMIR_b_LTActPumpRPMTgtPct, provided-interface=FsftPMIR_b_LTActPumpRPMTgtPct
      FsftPMIR_b_LTActPumpSuppVltErr: server-com-spec=FsftPMIR_b_LTActPumpSuppVltErr, provided-interface=FsftPMIR_b_LTActPumpSuppVltErr
      FsftPMIR_b_LTActPumpTemp: server-com-spec=FsftPMIR_b_LTActPumpTemp, provided-interface=FsftPMIR_b_LTActPumpTemp
      FsftPMIR_b_LTActPumpVlt: server-com-spec=FsftPMIR_b_LTActPumpVlt, provided-interface=FsftPMIR_b_LTActPumpVlt
      FsftPMIR_b_LTPsvPmp2AirPrsntErr: server-com-spec=FsftPMIR_b_LTPsvPmp2AirPrsntErr, provided-interface=FsftPMIR_b_LTPsvPmp2AirPrsntErr
      FsftPMIR_b_LTPsvPmpAirPrsntErr: server-com-spec=FsftPMIR_b_LTPsvPmpAirPrsntErr, provided-interface=FsftPMIR_b_LTPsvPmpAirPrsntErr
      FsftPMIR_b_LTPsvPump2Deblock: server-com-spec=FsftPMIR_b_LTPsvPump2Deblock, provided-interface=FsftPMIR_b_LTPsvPump2Deblock
      FsftPMIR_b_LTPsvPump2DryRun: server-com-spec=FsftPMIR_b_LTPsvPump2DryRun, provided-interface=FsftPMIR_b_LTPsvPump2DryRun
      FsftPMIR_b_LTPsvPump2Failsafe: server-com-spec=FsftPMIR_b_LTPsvPump2Failsafe, provided-interface=FsftPMIR_b_LTPsvPump2Failsafe
      FsftPMIR_b_LTPsvPump2MntrRPM: server-com-spec=FsftPMIR_b_LTPsvPump2MntrRPM, provided-interface=FsftPMIR_b_LTPsvPump2MntrRPM
      FsftPMIR_b_LTPsvPump2NodeErr: server-com-spec=FsftPMIR_b_LTPsvPump2NodeErr, provided-interface=FsftPMIR_b_LTPsvPump2NodeErr
      FsftPMIR_b_LTPsvPump2OvrCrnt: server-com-spec=FsftPMIR_b_LTPsvPump2OvrCrnt, provided-interface=FsftPMIR_b_LTPsvPump2OvrCrnt
      FsftPMIR_b_LTPsvPump2RPMAct: server-com-spec=FsftPMIR_b_LTPsvPump2RPMAct, provided-interface=FsftPMIR_b_LTPsvPump2RPMAct
      FsftPMIR_b_LTPsvPump2RPMActPct: server-com-spec=FsftPMIR_b_LTPsvPump2RPMActPct, provided-interface=FsftPMIR_b_LTPsvPump2RPMActPct
      FsftPMIR_b_LTPsvPump2RPMTgtPct: server-com-spec=FsftPMIR_b_LTPsvPump2RPMTgtPct, provided-interface=FsftPMIR_b_LTPsvPump2RPMTgtPct
      FsftPMIR_b_LTPsvPump2SuppVltErr: server-com-spec=FsftPMIR_b_LTPsvPump2SuppVltErr, provided-interface=FsftPMIR_b_LTPsvPump2SuppVltErr
      FsftPMIR_b_LTPsvPump2Temp: server-com-spec=FsftPMIR_b_LTPsvPump2Temp, provided-interface=FsftPMIR_b_LTPsvPump2Temp
      FsftPMIR_b_LTPsvPump2_LmpHM: server-com-spec=FsftPMIR_b_LTPsvPump2_LmpHM, provided-interface=FsftPMIR_b_LTPsvPump2_LmpHM
      FsftPMIR_b_LTPsvPumpDeblock: server-com-spec=FsftPMIR_b_LTPsvPumpDeblock, provided-interface=FsftPMIR_b_LTPsvPumpDeblock
      FsftPMIR_b_LTPsvPumpDryRun: server-com-spec=FsftPMIR_b_LTPsvPumpDryRun, provided-interface=FsftPMIR_b_LTPsvPumpDryRun
      FsftPMIR_b_LTPsvPumpFailsafe: server-com-spec=FsftPMIR_b_LTPsvPumpFailsafe, provided-interface=FsftPMIR_b_LTPsvPumpFailsafe
      FsftPMIR_b_LTPsvPumpMntrRPM: server-com-spec=FsftPMIR_b_LTPsvPumpMntrRPM, provided-interface=FsftPMIR_b_LTPsvPumpMntrRPM
      FsftPMIR_b_LTPsvPumpNodeErr: server-com-spec=FsftPMIR_b_LTPsvPumpNodeErr, provided-interface=FsftPMIR_b_LTPsvPumpNodeErr
      FsftPMIR_b_LTPsvPumpOvrCrnt: server-com-spec=FsftPMIR_b_LTPsvPumpOvrCrnt, provided-interface=FsftPMIR_b_LTPsvPumpOvrCrnt
      FsftPMIR_b_LTPsvPumpRPMAct: server-com-spec=FsftPMIR_b_LTPsvPumpRPMAct, provided-interface=FsftPMIR_b_LTPsvPumpRPMAct
      FsftPMIR_b_LTPsvPumpRPMActPct: server-com-spec=FsftPMIR_b_LTPsvPumpRPMActPct, provided-interface=FsftPMIR_b_LTPsvPumpRPMActPct
      FsftPMIR_b_LTPsvPumpRPMTgt: server-com-spec=FsftPMIR_b_LTPsvPumpRPMTgt, provided-interface=FsftPMIR_b_LTPsvPumpRPMTgt
      FsftPMIR_b_LTPsvPumpRPMTgtPct: server-com-spec=FsftPMIR_b_LTPsvPumpRPMTgtPct, provided-interface=FsftPMIR_b_LTPsvPumpRPMTgtPct
      FsftPMIR_b_LTPsvPumpSuppVltErr: server-com-spec=FsftPMIR_b_LTPsvPumpSuppVltErr, provided-interface=FsftPMIR_b_LTPsvPumpSuppVltErr
      FsftPMIR_b_LTPsvPumpTemp: server-com-spec=FsftPMIR_b_LTPsvPumpTemp, provided-interface=FsftPMIR_b_LTPsvPumpTemp
      FsftPMIR_b_LTPsvPump_LmpHM: server-com-spec=FsftPMIR_b_LTPsvPump_LmpHM, provided-interface=FsftPMIR_b_LTPsvPump_LmpHM
      FsftPMIR_b_LT_ActvPmpOT: server-com-spec=FsftPMIR_b_LT_ActvPmpOT, provided-interface=FsftPMIR_b_LT_ActvPmpOT
      FsftPMIR_b_LT_PsvPmp2Crnt: server-com-spec=FsftPMIR_b_LT_PsvPmp2Crnt, provided-interface=FsftPMIR_b_LT_PsvPmp2Crnt
      FsftPMIR_b_LT_PsvPmp2OT: server-com-spec=FsftPMIR_b_LT_PsvPmp2OT, provided-interface=FsftPMIR_b_LT_PsvPmp2OT
      FsftPMIR_b_LT_PsvPmp2Vltg: server-com-spec=FsftPMIR_b_LT_PsvPmp2Vltg, provided-interface=FsftPMIR_b_LT_PsvPmp2Vltg
      FsftPMIR_b_LT_PsvPmpCrnt: server-com-spec=FsftPMIR_b_LT_PsvPmpCrnt, provided-interface=FsftPMIR_b_LT_PsvPmpCrnt
      FsftPMIR_b_LT_PsvPmpOT: server-com-spec=FsftPMIR_b_LT_PsvPmpOT, provided-interface=FsftPMIR_b_LT_PsvPmpOT
      FsftPMIR_b_LT_PsvPmpVltg: server-com-spec=FsftPMIR_b_LT_PsvPmpVltg, provided-interface=FsftPMIR_b_LT_PsvPmpVltg
      FsftPMIR_b_TransAuxPmp2_ColdBiasSts: server-com-spec=FsftPMIR_b_TransAuxPmp2_ColdBiasSts, provided-interface=FsftPMIR_b_TransAuxPmp2_ColdBiasSts
      FsftPMIR_b_TransAuxPmp2_Crnt: server-com-spec=FsftPMIR_b_TransAuxPmp2_Crnt, provided-interface=FsftPMIR_b_TransAuxPmp2_Crnt
      FsftPMIR_b_TransAuxPmp2_CrntErr: server-com-spec=FsftPMIR_b_TransAuxPmp2_CrntErr, provided-interface=FsftPMIR_b_TransAuxPmp2_CrntErr
      FsftPMIR_b_TransAuxPmp2_DryRun: server-com-spec=FsftPMIR_b_TransAuxPmp2_DryRun, provided-interface=FsftPMIR_b_TransAuxPmp2_DryRun
      FsftPMIR_b_TransAuxPmp2_LmpHM: server-com-spec=FsftPMIR_b_TransAuxPmp2_LmpHM, provided-interface=FsftPMIR_b_TransAuxPmp2_LmpHM
      FsftPMIR_b_TransAuxPmp2_MntrRPM: server-com-spec=FsftPMIR_b_TransAuxPmp2_MntrRPM, provided-interface=FsftPMIR_b_TransAuxPmp2_MntrRPM
      FsftPMIR_b_TransAuxPmp2_OilTemp: server-com-spec=FsftPMIR_b_TransAuxPmp2_OilTemp, provided-interface=FsftPMIR_b_TransAuxPmp2_OilTemp
      FsftPMIR_b_TransAuxPmp2_PstRnSt: server-com-spec=FsftPMIR_b_TransAuxPmp2_PstRnSt, provided-interface=FsftPMIR_b_TransAuxPmp2_PstRnSt
      FsftPMIR_b_TransAuxPmp2_RPMAct: server-com-spec=FsftPMIR_b_TransAuxPmp2_RPMAct, provided-interface=FsftPMIR_b_TransAuxPmp2_RPMAct
      FsftPMIR_b_TransAuxPmp2_RPMTgt: server-com-spec=FsftPMIR_b_TransAuxPmp2_RPMTgt, provided-interface=FsftPMIR_b_TransAuxPmp2_RPMTgt
      FsftPMIR_b_TransAuxPmp2_RespErr: server-com-spec=FsftPMIR_b_TransAuxPmp2_RespErr, provided-interface=FsftPMIR_b_TransAuxPmp2_RespErr
      FsftPMIR_b_TransAuxPmp2_StallEvnt: server-com-spec=FsftPMIR_b_TransAuxPmp2_StallEvnt, provided-interface=FsftPMIR_b_TransAuxPmp2_StallEvnt
      FsftPMIR_b_TransAuxPmp2_Temp: server-com-spec=FsftPMIR_b_TransAuxPmp2_Temp, provided-interface=FsftPMIR_b_TransAuxPmp2_Temp
      FsftPMIR_b_TransAuxPmp2_TempErr: server-com-spec=FsftPMIR_b_TransAuxPmp2_TempErr, provided-interface=FsftPMIR_b_TransAuxPmp2_TempErr
      FsftPMIR_b_TransAuxPmp2_Vltg: server-com-spec=FsftPMIR_b_TransAuxPmp2_Vltg, provided-interface=FsftPMIR_b_TransAuxPmp2_Vltg
      FsftPMIR_b_TransAuxPmp2_VltgErr: server-com-spec=FsftPMIR_b_TransAuxPmp2_VltgErr, provided-interface=FsftPMIR_b_TransAuxPmp2_VltgErr
      FsftPMIR_b_TransAuxPmp_ColdBiasSts: server-com-spec=FsftPMIR_b_TransAuxPmp_ColdBiasSts, provided-interface=FsftPMIR_b_TransAuxPmp_ColdBiasSts
      FsftPMIR_b_TransAuxPmp_Crnt: server-com-spec=FsftPMIR_b_TransAuxPmp_Crnt, provided-interface=FsftPMIR_b_TransAuxPmp_Crnt
      FsftPMIR_b_TransAuxPmp_CrntErr: server-com-spec=FsftPMIR_b_TransAuxPmp_CrntErr, provided-interface=FsftPMIR_b_TransAuxPmp_CrntErr
      FsftPMIR_b_TransAuxPmp_DryRun: server-com-spec=FsftPMIR_b_TransAuxPmp_DryRun, provided-interface=FsftPMIR_b_TransAuxPmp_DryRun
      FsftPMIR_b_TransAuxPmp_LmpHM: server-com-spec=FsftPMIR_b_TransAuxPmp_LmpHM, provided-interface=FsftPMIR_b_TransAuxPmp_LmpHM
      FsftPMIR_b_TransAuxPmp_MntrRPM: server-com-spec=FsftPMIR_b_TransAuxPmp_MntrRPM, provided-interface=FsftPMIR_b_TransAuxPmp_MntrRPM
      FsftPMIR_b_TransAuxPmp_OilTemp: server-com-spec=FsftPMIR_b_TransAuxPmp_OilTemp, provided-interface=FsftPMIR_b_TransAuxPmp_OilTemp
      FsftPMIR_b_TransAuxPmp_PstRnSt: server-com-spec=FsftPMIR_b_TransAuxPmp_PstRnSt, provided-interface=FsftPMIR_b_TransAuxPmp_PstRnSt
      FsftPMIR_b_TransAuxPmp_RPMAct: server-com-spec=FsftPMIR_b_TransAuxPmp_RPMAct, provided-interface=FsftPMIR_b_TransAuxPmp_RPMAct
      FsftPMIR_b_TransAuxPmp_RPMTgt: server-com-spec=FsftPMIR_b_TransAuxPmp_RPMTgt, provided-interface=FsftPMIR_b_TransAuxPmp_RPMTgt
      FsftPMIR_b_TransAuxPmp_RespErr: server-com-spec=FsftPMIR_b_TransAuxPmp_RespErr, provided-interface=FsftPMIR_b_TransAuxPmp_RespErr
      FsftPMIR_b_TransAuxPmp_StallEvnt: server-com-spec=FsftPMIR_b_TransAuxPmp_StallEvnt, provided-interface=FsftPMIR_b_TransAuxPmp_StallEvnt
      FsftPMIR_b_TransAuxPmp_Temp: server-com-spec=FsftPMIR_b_TransAuxPmp_Temp, provided-interface=FsftPMIR_b_TransAuxPmp_Temp
      FsftPMIR_b_TransAuxPmp_TempErr: server-com-spec=FsftPMIR_b_TransAuxPmp_TempErr, provided-interface=FsftPMIR_b_TransAuxPmp_TempErr
      FsftPMIR_b_TransAuxPmp_Vltg: server-com-spec=FsftPMIR_b_TransAuxPmp_Vltg, provided-interface=FsftPMIR_b_TransAuxPmp_Vltg
      FsftPMIR_b_TransAuxPmp_VltgErr: server-com-spec=FsftPMIR_b_TransAuxPmp_VltgErr, provided-interface=FsftPMIR_b_TransAuxPmp_VltgErr
      FsftPMPR_e_LTPsvPump2_PstRnSt: server-com-spec=FsftPMPR_e_LTPsvPump2_PstRnSt, provided-interface=FsftPMPR_e_LTPsvPump2_PstRnSt
      FsftPMPR_e_LTPsvPump_PstRnSt: server-com-spec=FsftPMPR_e_LTPsvPump_PstRnSt, provided-interface=FsftPMPR_e_LTPsvPump_PstRnSt
      PokePMIF_DVC_HT_AuxPmpCmd: server-com-spec{operation=PokePMIF_DVC_HT_AuxPmpCmd, queue-length=1}, provided-interface=PokePMIF_DVC_HT_AuxPmpCmd
      PokePMIF_DVC_LT_ActvPmpCmd: server-com-spec{operation=PokePMIF_DVC_LT_ActvPmpCmd, queue-length=1}, provided-interface=PokePMIF_DVC_LT_ActvPmpCmd
      PokePMIF_DVC_LT_PsvPmpCmd: server-com-spec{operation=PokePMIF_DVC_LT_PsvPmpCmd, queue-length=1}, provided-interface=PokePMIF_DVC_LT_PsvPmpCmd
      PokePMIR_I_FCCPmpSuppCrnt: server-com-spec{operation=PokePMIR_I_FCCPmpSuppCrnt, queue-length=1}, provided-interface=PokePMIR_I_FCCPmpSuppCrnt
      PokePMIR_I_HT_AuxPmpCrnt: server-com-spec{operation=PokePMIR_I_HT_AuxPmpCrnt, queue-length=1}, provided-interface=PokePMIR_I_HT_AuxPmpCrnt
      PokePMIR_I_LTActPumpCrnt: server-com-spec{operation=PokePMIR_I_LTActPumpCrnt, queue-length=1}, provided-interface=PokePMIR_I_LTActPumpCrnt
      PokePMIR_I_LT_PsvPmp2Crnt: server-com-spec{operation=PokePMIR_I_LT_PsvPmp2Crnt, queue-length=1}, provided-interface=PokePMIR_I_LT_PsvPmp2Crnt
      PokePMIR_I_LT_PsvPmpCrnt: server-com-spec{operation=PokePMIR_I_LT_PsvPmpCrnt, queue-length=1}, provided-interface=PokePMIR_I_LT_PsvPmpCrnt
      PokePMIR_I_TransAuxPmp2_Crnt: server-com-spec{operation=PokePMIR_I_TransAuxPmp2_Crnt, queue-length=1}, provided-interface=PokePMIR_I_TransAuxPmp2_Crnt
      PokePMIR_I_TransAuxPmp_Crnt: server-com-spec{operation=PokePMIR_I_TransAuxPmp_Crnt, queue-length=1}, provided-interface=PokePMIR_I_TransAuxPmp_Crnt
      PokePMIR_Pct_ECM_LTPsvPmpRq: server-com-spec{operation=PokePMIR_Pct_ECM_LTPsvPmpRq, queue-length=1}, provided-interface=PokePMIR_Pct_ECM_LTPsvPmpRq
      PokePMIR_Pct_HTAuxPumpRPMAct: server-com-spec{operation=PokePMIR_Pct_HTAuxPumpRPMAct, queue-length=1}, provided-interface=PokePMIR_Pct_HTAuxPumpRPMAct
      PokePMIR_Pct_HTAuxPumpRPMTgt: server-com-spec{operation=PokePMIR_Pct_HTAuxPumpRPMTgt, queue-length=1}, provided-interface=PokePMIR_Pct_HTAuxPumpRPMTgt
      PokePMIR_Pct_LTActPumpRPMAct: server-com-spec{operation=PokePMIR_Pct_LTActPumpRPMAct, queue-length=1}, provided-interface=PokePMIR_Pct_LTActPumpRPMAct
      PokePMIR_Pct_LTActPumpRPMTgt: server-com-spec{operation=PokePMIR_Pct_LTActPumpRPMTgt, queue-length=1}, provided-interface=PokePMIR_Pct_LTActPumpRPMTgt
      PokePMIR_Pct_LTPsvPump2RPMAct: server-com-spec{operation=PokePMIR_Pct_LTPsvPump2RPMAct, queue-length=1}, provided-interface=PokePMIR_Pct_LTPsvPump2RPMAct
      PokePMIR_Pct_LTPsvPump2RPMTgt: server-com-spec{operation=PokePMIR_Pct_LTPsvPump2RPMTgt, queue-length=1}, provided-interface=PokePMIR_Pct_LTPsvPump2RPMTgt
      PokePMIR_Pct_LTPsvPumpRPMAct: server-com-spec{operation=PokePMIR_Pct_LTPsvPumpRPMAct, queue-length=1}, provided-interface=PokePMIR_Pct_LTPsvPumpRPMAct
      PokePMIR_Pct_LTPsvPumpRPMTgt: server-com-spec{operation=PokePMIR_Pct_LTPsvPumpRPMTgt, queue-length=1}, provided-interface=PokePMIR_Pct_LTPsvPumpRPMTgt
      PokePMIR_T_FCCPmpActTemp: server-com-spec{operation=PokePMIR_T_FCCPmpActTemp, queue-length=1}, provided-interface=PokePMIR_T_FCCPmpActTemp
      PokePMIR_T_HT_AuxPmpTemp: server-com-spec{operation=PokePMIR_T_HT_AuxPmpTemp, queue-length=1}, provided-interface=PokePMIR_T_HT_AuxPmpTemp
      PokePMIR_T_LTActPumpTemp: server-com-spec{operation=PokePMIR_T_LTActPumpTemp, queue-length=1}, provided-interface=PokePMIR_T_LTActPumpTemp
      PokePMIR_T_LTPsvPump2Temp: server-com-spec{operation=PokePMIR_T_LTPsvPump2Temp, queue-length=1}, provided-interface=PokePMIR_T_LTPsvPump2Temp
      PokePMIR_T_LTPsvPumpTemp: server-com-spec{operation=PokePMIR_T_LTPsvPumpTemp, queue-length=1}, provided-interface=PokePMIR_T_LTPsvPumpTemp
      PokePMIR_T_TransAuxPmp2_OilTemp: server-com-spec{operation=PokePMIR_T_TransAuxPmp2_OilTemp, queue-length=1}, provided-interface=PokePMIR_T_TransAuxPmp2_OilTemp
      PokePMIR_T_TransAuxPmp2_Temp: server-com-spec{operation=PokePMIR_T_TransAuxPmp2_Temp, queue-length=1}, provided-interface=PokePMIR_T_TransAuxPmp2_Temp
      PokePMIR_T_TransAuxPmp_OilTemp: server-com-spec{operation=PokePMIR_T_TransAuxPmp_OilTemp, queue-length=1}, provided-interface=PokePMIR_T_TransAuxPmp_OilTemp
      PokePMIR_T_TransAuxPmp_Temp: server-com-spec{operation=PokePMIR_T_TransAuxPmp_Temp, queue-length=1}, provided-interface=PokePMIR_T_TransAuxPmp_Temp
      PokePMIR_U_FCCPmpActVlt: server-com-spec{operation=PokePMIR_U_FCCPmpActVlt, queue-length=1}, provided-interface=PokePMIR_U_FCCPmpActVlt
      PokePMIR_U_HT_AuxPmpVltg: server-com-spec{operation=PokePMIR_U_HT_AuxPmpVltg, queue-length=1}, provided-interface=PokePMIR_U_HT_AuxPmpVltg
      PokePMIR_U_LTActPumpVlt: server-com-spec{operation=PokePMIR_U_LTActPumpVlt, queue-length=1}, provided-interface=PokePMIR_U_LTActPumpVlt
      PokePMIR_U_LT_PsvPmp2Vltg: server-com-spec{operation=PokePMIR_U_LT_PsvPmp2Vltg, queue-length=1}, provided-interface=PokePMIR_U_LT_PsvPmp2Vltg
      PokePMIR_U_LT_PsvPmpVltg: server-com-spec{operation=PokePMIR_U_LT_PsvPmpVltg, queue-length=1}, provided-interface=PokePMIR_U_LT_PsvPmpVltg
      PokePMIR_U_TransAuxPmp2_Vltg: server-com-spec{operation=PokePMIR_U_TransAuxPmp2_Vltg, queue-length=1}, provided-interface=PokePMIR_U_TransAuxPmp2_Vltg
      PokePMIR_U_TransAuxPmp_Vltg: server-com-spec{operation=PokePMIR_U_TransAuxPmp_Vltg, queue-length=1}, provided-interface=PokePMIR_U_TransAuxPmp_Vltg
      PokePMIR_b_FCCPmpErrLIN: server-com-spec{operation=PokePMIR_b_FCCPmpErrLIN, queue-length=1}, provided-interface=PokePMIR_b_FCCPmpErrLIN
      PokePMIR_b_FCCPmpErrLLO: server-com-spec{operation=PokePMIR_b_FCCPmpErrLLO, queue-length=1}, provided-interface=PokePMIR_b_FCCPmpErrLLO
      PokePMIR_b_FCCPmpErrOC: server-com-spec{operation=PokePMIR_b_FCCPmpErrOC, queue-length=1}, provided-interface=PokePMIR_b_FCCPmpErrOC
      PokePMIR_b_FCCPmpErrOT: server-com-spec{operation=PokePMIR_b_FCCPmpErrOT, queue-length=1}, provided-interface=PokePMIR_b_FCCPmpErrOT
      PokePMIR_b_FCCPmpErrOTD: server-com-spec{operation=PokePMIR_b_FCCPmpErrOTD, queue-length=1}, provided-interface=PokePMIR_b_FCCPmpErrOTD
      PokePMIR_b_FCCPmpErrOV: server-com-spec{operation=PokePMIR_b_FCCPmpErrOV, queue-length=1}, provided-interface=PokePMIR_b_FCCPmpErrOV
      PokePMIR_b_FCCPmpErrSC: server-com-spec{operation=PokePMIR_b_FCCPmpErrSC, queue-length=1}, provided-interface=PokePMIR_b_FCCPmpErrSC
      PokePMIR_b_FCCPmpErrUV: server-com-spec{operation=PokePMIR_b_FCCPmpErrUV, queue-length=1}, provided-interface=PokePMIR_b_FCCPmpErrUV
      PokePMIR_b_FCCPmpErrVD: server-com-spec{operation=PokePMIR_b_FCCPmpErrVD, queue-length=1}, provided-interface=PokePMIR_b_FCCPmpErrVD
      PokePMIR_b_FCCPmpIntFlt: server-com-spec{operation=PokePMIR_b_FCCPmpIntFlt, queue-length=1}, provided-interface=PokePMIR_b_FCCPmpIntFlt
      PokePMIR_b_FCCPmpStlFlt: server-com-spec{operation=PokePMIR_b_FCCPmpStlFlt, queue-length=1}, provided-interface=PokePMIR_b_FCCPmpStlFlt
      PokePMIR_b_HTAuxPumpRespErr: server-com-spec{operation=PokePMIR_b_HTAuxPumpRespErr, queue-length=1}, provided-interface=PokePMIR_b_HTAuxPumpRespErr
      PokePMIR_b_LTActPumpRespErr: server-com-spec{operation=PokePMIR_b_LTActPumpRespErr, queue-length=1}, provided-interface=PokePMIR_b_LTActPumpRespErr
      PokePMIR_b_LTPsvPump2RespErr: server-com-spec{operation=PokePMIR_b_LTPsvPump2RespErr, queue-length=1}, provided-interface=PokePMIR_b_LTPsvPump2RespErr
      PokePMIR_b_LTPsvPumpRespErr: server-com-spec{operation=PokePMIR_b_LTPsvPumpRespErr, queue-length=1}, provided-interface=PokePMIR_b_LTPsvPumpRespErr
      PokePMIR_b_TransAuxPmp2_RespErr: server-com-spec{operation=PokePMIR_b_TransAuxPmp2_RespErr, queue-length=1}, provided-interface=PokePMIR_b_TransAuxPmp2_RespErr
      PokePMIR_b_TransAuxPmp_RespErr: server-com-spec{operation=PokePMIR_b_TransAuxPmp_RespErr, queue-length=1}, provided-interface=PokePMIR_b_TransAuxPmp_RespErr
      PokePMIR_b_TransAuxPmp_TCM_Req: server-com-spec{operation=PokePMIR_b_TransAuxPmp_TCM_Req, queue-length=1}, provided-interface=PokePMIR_b_TransAuxPmp_TCM_Req
      PokePMIR_e_HTAuxPmpAirPrsntErr: server-com-spec{operation=PokePMIR_e_HTAuxPmpAirPrsntErr, queue-length=1}, provided-interface=PokePMIR_e_HTAuxPmpAirPrsntErr
      PokePMIR_e_HTAuxPmpProdSuplr_ID: server-com-spec{operation=PokePMIR_e_HTAuxPmpProdSuplr_ID, queue-length=1}, provided-interface=PokePMIR_e_HTAuxPmpProdSuplr_ID
      PokePMIR_e_HTAuxPumpDeblock: server-com-spec{operation=PokePMIR_e_HTAuxPumpDeblock, queue-length=1}, provided-interface=PokePMIR_e_HTAuxPumpDeblock
      PokePMIR_e_HTAuxPumpDryRun: server-com-spec{operation=PokePMIR_e_HTAuxPumpDryRun, queue-length=1}, provided-interface=PokePMIR_e_HTAuxPumpDryRun
      PokePMIR_e_HTAuxPumpFailsafe: server-com-spec{operation=PokePMIR_e_HTAuxPumpFailsafe, queue-length=1}, provided-interface=PokePMIR_e_HTAuxPumpFailsafe
      PokePMIR_e_HTAuxPumpNodeErr: server-com-spec{operation=PokePMIR_e_HTAuxPumpNodeErr, queue-length=1}, provided-interface=PokePMIR_e_HTAuxPumpNodeErr
      PokePMIR_e_HTAuxPumpOvrCrnt: server-com-spec{operation=PokePMIR_e_HTAuxPumpOvrCrnt, queue-length=1}, provided-interface=PokePMIR_e_HTAuxPumpOvrCrnt
      PokePMIR_e_HTAuxPumpSuppVltErr: server-com-spec{operation=PokePMIR_e_HTAuxPumpSuppVltErr, queue-length=1}, provided-interface=PokePMIR_e_HTAuxPumpSuppVltErr
      PokePMIR_e_HTAuxPump_LmpHM: server-com-spec{operation=PokePMIR_e_HTAuxPump_LmpHM, queue-length=1}, provided-interface=PokePMIR_e_HTAuxPump_LmpHM
      PokePMIR_e_HT_AuxPmpMntrRPM: server-com-spec{operation=PokePMIR_e_HT_AuxPmpMntrRPM, queue-length=1}, provided-interface=PokePMIR_e_HT_AuxPmpMntrRPM
      PokePMIR_e_HT_AuxPmpOT: server-com-spec{operation=PokePMIR_e_HT_AuxPmpOT, queue-length=1}, provided-interface=PokePMIR_e_HT_AuxPmpOT
      PokePMIR_e_HT_AuxPmp_PstRnSt: server-com-spec{operation=PokePMIR_e_HT_AuxPmp_PstRnSt, queue-length=1}, provided-interface=PokePMIR_e_HT_AuxPmp_PstRnSt
      PokePMIR_e_LTActPumpAirPrsntErr: server-com-spec{operation=PokePMIR_e_LTActPumpAirPrsntErr, queue-length=1}, provided-interface=PokePMIR_e_LTActPumpAirPrsntErr
      PokePMIR_e_LTActPumpDeblock: server-com-spec{operation=PokePMIR_e_LTActPumpDeblock, queue-length=1}, provided-interface=PokePMIR_e_LTActPumpDeblock
      PokePMIR_e_LTActPumpDryRun: server-com-spec{operation=PokePMIR_e_LTActPumpDryRun, queue-length=1}, provided-interface=PokePMIR_e_LTActPumpDryRun
      PokePMIR_e_LTActPumpFailsafe: server-com-spec{operation=PokePMIR_e_LTActPumpFailsafe, queue-length=1}, provided-interface=PokePMIR_e_LTActPumpFailsafe
      PokePMIR_e_LTActPumpLmpHM: server-com-spec{operation=PokePMIR_e_LTActPumpLmpHM, queue-length=1}, provided-interface=PokePMIR_e_LTActPumpLmpHM
      PokePMIR_e_LTActPumpMntrRPM: server-com-spec{operation=PokePMIR_e_LTActPumpMntrRPM, queue-length=1}, provided-interface=PokePMIR_e_LTActPumpMntrRPM
      PokePMIR_e_LTActPumpNodeErr: server-com-spec{operation=PokePMIR_e_LTActPumpNodeErr, queue-length=1}, provided-interface=PokePMIR_e_LTActPumpNodeErr
      PokePMIR_e_LTActPumpOvrCrnt: server-com-spec{operation=PokePMIR_e_LTActPumpOvrCrnt, queue-length=1}, provided-interface=PokePMIR_e_LTActPumpOvrCrnt
      PokePMIR_e_LTActPumpProdSuplr: server-com-spec{operation=PokePMIR_e_LTActPumpProdSuplr, queue-length=1}, provided-interface=PokePMIR_e_LTActPumpProdSuplr
      PokePMIR_e_LTActPumpPstRnSt: server-com-spec{operation=PokePMIR_e_LTActPumpPstRnSt, queue-length=1}, provided-interface=PokePMIR_e_LTActPumpPstRnSt
      PokePMIR_e_LTActPumpSuppVltErr: server-com-spec{operation=PokePMIR_e_LTActPumpSuppVltErr, queue-length=1}, provided-interface=PokePMIR_e_LTActPumpSuppVltErr
      PokePMIR_e_LTPsvPmp2AirPrsntErr: server-com-spec{operation=PokePMIR_e_LTPsvPmp2AirPrsntErr, queue-length=1}, provided-interface=PokePMIR_e_LTPsvPmp2AirPrsntErr
      PokePMIR_e_LTPsvPmp2ProdSuplr_ID: server-com-spec{operation=PokePMIR_e_LTPsvPmp2ProdSuplr_ID, queue-length=1}, provided-interface=PokePMIR_e_LTPsvPmp2ProdSuplr_ID
      PokePMIR_e_LTPsvPmpAirPrsntErr: server-com-spec{operation=PokePMIR_e_LTPsvPmpAirPrsntErr, queue-length=1}, provided-interface=PokePMIR_e_LTPsvPmpAirPrsntErr
      PokePMIR_e_LTPsvPmpProdSuplr_ID: server-com-spec{operation=PokePMIR_e_LTPsvPmpProdSuplr_ID, queue-length=1}, provided-interface=PokePMIR_e_LTPsvPmpProdSuplr_ID
      PokePMIR_e_LTPsvPump2Deblock: server-com-spec{operation=PokePMIR_e_LTPsvPump2Deblock, queue-length=1}, provided-interface=PokePMIR_e_LTPsvPump2Deblock
      PokePMIR_e_LTPsvPump2DryRun: server-com-spec{operation=PokePMIR_e_LTPsvPump2DryRun, queue-length=1}, provided-interface=PokePMIR_e_LTPsvPump2DryRun
      PokePMIR_e_LTPsvPump2Failsafe: server-com-spec{operation=PokePMIR_e_LTPsvPump2Failsafe, queue-length=1}, provided-interface=PokePMIR_e_LTPsvPump2Failsafe
      PokePMIR_e_LTPsvPump2MntrRPM: server-com-spec{operation=PokePMIR_e_LTPsvPump2MntrRPM, queue-length=1}, provided-interface=PokePMIR_e_LTPsvPump2MntrRPM
      PokePMIR_e_LTPsvPump2NodeErr: server-com-spec{operation=PokePMIR_e_LTPsvPump2NodeErr, queue-length=1}, provided-interface=PokePMIR_e_LTPsvPump2NodeErr
      PokePMIR_e_LTPsvPump2OvrCrnt: server-com-spec{operation=PokePMIR_e_LTPsvPump2OvrCrnt, queue-length=1}, provided-interface=PokePMIR_e_LTPsvPump2OvrCrnt
      PokePMIR_e_LTPsvPump2SuppVltErr: server-com-spec{operation=PokePMIR_e_LTPsvPump2SuppVltErr, queue-length=1}, provided-interface=PokePMIR_e_LTPsvPump2SuppVltErr
      PokePMIR_e_LTPsvPump2_LmpHM: server-com-spec{operation=PokePMIR_e_LTPsvPump2_LmpHM, queue-length=1}, provided-interface=PokePMIR_e_LTPsvPump2_LmpHM
      PokePMIR_e_LTPsvPumpDeblock: server-com-spec{operation=PokePMIR_e_LTPsvPumpDeblock, queue-length=1}, provided-interface=PokePMIR_e_LTPsvPumpDeblock
      PokePMIR_e_LTPsvPumpDryRun: server-com-spec{operation=PokePMIR_e_LTPsvPumpDryRun, queue-length=1}, provided-interface=PokePMIR_e_LTPsvPumpDryRun
      PokePMIR_e_LTPsvPumpFailsafe: server-com-spec{operation=PokePMIR_e_LTPsvPumpFailsafe, queue-length=1}, provided-interface=PokePMIR_e_LTPsvPumpFailsafe
      PokePMIR_e_LTPsvPumpMntrRPM: server-com-spec{operation=PokePMIR_e_LTPsvPumpMntrRPM, queue-length=1}, provided-interface=PokePMIR_e_LTPsvPumpMntrRPM
      PokePMIR_e_LTPsvPumpNodeErr: server-com-spec{operation=PokePMIR_e_LTPsvPumpNodeErr, queue-length=1}, provided-interface=PokePMIR_e_LTPsvPumpNodeErr
      PokePMIR_e_LTPsvPumpOvrCrnt: server-com-spec{operation=PokePMIR_e_LTPsvPumpOvrCrnt, queue-length=1}, provided-interface=PokePMIR_e_LTPsvPumpOvrCrnt
      PokePMIR_e_LTPsvPumpSuppVltErr: server-com-spec{operation=PokePMIR_e_LTPsvPumpSuppVltErr, queue-length=1}, provided-interface=PokePMIR_e_LTPsvPumpSuppVltErr
      PokePMIR_e_LTPsvPump_LmpHM: server-com-spec{operation=PokePMIR_e_LTPsvPump_LmpHM, queue-length=1}, provided-interface=PokePMIR_e_LTPsvPump_LmpHM
      PokePMIR_e_LT_ActvPmpOT: server-com-spec{operation=PokePMIR_e_LT_ActvPmpOT, queue-length=1}, provided-interface=PokePMIR_e_LT_ActvPmpOT
      PokePMIR_e_LT_PsvPmp2OT: server-com-spec{operation=PokePMIR_e_LT_PsvPmp2OT, queue-length=1}, provided-interface=PokePMIR_e_LT_PsvPmp2OT
      PokePMIR_e_LT_PsvPmpOT: server-com-spec{operation=PokePMIR_e_LT_PsvPmpOT, queue-length=1}, provided-interface=PokePMIR_e_LT_PsvPmpOT
      PokePMIR_e_TransAuxPmp2_ColdBiasSts: server-com-spec{operation=PokePMIR_e_TransAuxPmp2_ColdBiasSts, queue-length=1}, provided-interface=PokePMIR_e_TransAuxPmp2_ColdBiasSts
      PokePMIR_e_TransAuxPmp2_CrntErr: server-com-spec{operation=PokePMIR_e_TransAuxPmp2_CrntErr, queue-length=1}, provided-interface=PokePMIR_e_TransAuxPmp2_CrntErr
      PokePMIR_e_TransAuxPmp2_DryRun: server-com-spec{operation=PokePMIR_e_TransAuxPmp2_DryRun, queue-length=1}, provided-interface=PokePMIR_e_TransAuxPmp2_DryRun
      PokePMIR_e_TransAuxPmp2_LmpHM: server-com-spec{operation=PokePMIR_e_TransAuxPmp2_LmpHM, queue-length=1}, provided-interface=PokePMIR_e_TransAuxPmp2_LmpHM
      PokePMIR_e_TransAuxPmp2_MntrRPM: server-com-spec{operation=PokePMIR_e_TransAuxPmp2_MntrRPM, queue-length=1}, provided-interface=PokePMIR_e_TransAuxPmp2_MntrRPM
      PokePMIR_e_TransAuxPmp2_PstRnSt: server-com-spec{operation=PokePMIR_e_TransAuxPmp2_PstRnSt, queue-length=1}, provided-interface=PokePMIR_e_TransAuxPmp2_PstRnSt
      PokePMIR_e_TransAuxPmp2_StallEvnt: server-com-spec{operation=PokePMIR_e_TransAuxPmp2_StallEvnt, queue-length=1}, provided-interface=PokePMIR_e_TransAuxPmp2_StallEvnt
      PokePMIR_e_TransAuxPmp2_TempErr: server-com-spec{operation=PokePMIR_e_TransAuxPmp2_TempErr, queue-length=1}, provided-interface=PokePMIR_e_TransAuxPmp2_TempErr
      PokePMIR_e_TransAuxPmp2_VltgErr: server-com-spec{operation=PokePMIR_e_TransAuxPmp2_VltgErr, queue-length=1}, provided-interface=PokePMIR_e_TransAuxPmp2_VltgErr
      PokePMIR_e_TransAuxPmp_ColdBiasSts: server-com-spec{operation=PokePMIR_e_TransAuxPmp_ColdBiasSts, queue-length=1}, provided-interface=PokePMIR_e_TransAuxPmp_ColdBiasSts
      PokePMIR_e_TransAuxPmp_CrntErr: server-com-spec{operation=PokePMIR_e_TransAuxPmp_CrntErr, queue-length=1}, provided-interface=PokePMIR_e_TransAuxPmp_CrntErr
      PokePMIR_e_TransAuxPmp_DryRun: server-com-spec{operation=PokePMIR_e_TransAuxPmp_DryRun, queue-length=1}, provided-interface=PokePMIR_e_TransAuxPmp_DryRun
      PokePMIR_e_TransAuxPmp_LmpHM: server-com-spec{operation=PokePMIR_e_TransAuxPmp_LmpHM, queue-length=1}, provided-interface=PokePMIR_e_TransAuxPmp_LmpHM
      PokePMIR_e_TransAuxPmp_MntrRPM: server-com-spec{operation=PokePMIR_e_TransAuxPmp_MntrRPM, queue-length=1}, provided-interface=PokePMIR_e_TransAuxPmp_MntrRPM
      PokePMIR_e_TransAuxPmp_PstRnSt: server-com-spec{operation=PokePMIR_e_TransAuxPmp_PstRnSt, queue-length=1}, provided-interface=PokePMIR_e_TransAuxPmp_PstRnSt
      PokePMIR_e_TransAuxPmp_StallEvnt: server-com-spec{operation=PokePMIR_e_TransAuxPmp_StallEvnt, queue-length=1}, provided-interface=PokePMIR_e_TransAuxPmp_StallEvnt
      PokePMIR_e_TransAuxPmp_TempErr: server-com-spec{operation=PokePMIR_e_TransAuxPmp_TempErr, queue-length=1}, provided-interface=PokePMIR_e_TransAuxPmp_TempErr
      PokePMIR_e_TransAuxPmp_VltgErr: server-com-spec{operation=PokePMIR_e_TransAuxPmp_VltgErr, queue-length=1}, provided-interface=PokePMIR_e_TransAuxPmp_VltgErr
      PokePMIR_n_FCCPmpActSpd: server-com-spec{operation=PokePMIR_n_FCCPmpActSpd, queue-length=1}, provided-interface=PokePMIR_n_FCCPmpActSpd
      PokePMIR_n_HTAuxPumpPmpRPMTgt: server-com-spec{operation=PokePMIR_n_HTAuxPumpPmpRPMTgt, queue-length=1}, provided-interface=PokePMIR_n_HTAuxPumpPmpRPMTgt
      PokePMIR_n_HTAuxPumpRPMAct: server-com-spec{operation=PokePMIR_n_HTAuxPumpRPMAct, queue-length=1}, provided-interface=PokePMIR_n_HTAuxPumpRPMAct
      PokePMIR_n_LTActPumpRPMAct: server-com-spec{operation=PokePMIR_n_LTActPumpRPMAct, queue-length=1}, provided-interface=PokePMIR_n_LTActPumpRPMAct
      PokePMIR_n_LTActPumpRPMTgt: server-com-spec{operation=PokePMIR_n_LTActPumpRPMTgt, queue-length=1}, provided-interface=PokePMIR_n_LTActPumpRPMTgt
      PokePMIR_n_LTPsvPump2RPMAct: server-com-spec{operation=PokePMIR_n_LTPsvPump2RPMAct, queue-length=1}, provided-interface=PokePMIR_n_LTPsvPump2RPMAct
      PokePMIR_n_LTPsvPumpRPMAct: server-com-spec{operation=PokePMIR_n_LTPsvPumpRPMAct, queue-length=1}, provided-interface=PokePMIR_n_LTPsvPumpRPMAct
      PokePMIR_n_LTPsvPumpRPMTgt: server-com-spec{operation=PokePMIR_n_LTPsvPumpRPMTgt, queue-length=1}, provided-interface=PokePMIR_n_LTPsvPumpRPMTgt
      PokePMIR_n_TransAuxPmp2_RPMAct: server-com-spec{operation=PokePMIR_n_TransAuxPmp2_RPMAct, queue-length=1}, provided-interface=PokePMIR_n_TransAuxPmp2_RPMAct
      PokePMIR_n_TransAuxPmp2_RPMTgt: server-com-spec{operation=PokePMIR_n_TransAuxPmp2_RPMTgt, queue-length=1}, provided-interface=PokePMIR_n_TransAuxPmp2_RPMTgt
      PokePMIR_n_TransAuxPmp_RPMAct: server-com-spec{operation=PokePMIR_n_TransAuxPmp_RPMAct, queue-length=1}, provided-interface=PokePMIR_n_TransAuxPmp_RPMAct
      PokePMIR_n_TransAuxPmp_RPMTgt: server-com-spec{operation=PokePMIR_n_TransAuxPmp_RPMTgt, queue-length=1}, provided-interface=PokePMIR_n_TransAuxPmp_RPMTgt
      PokePMIR_y_HT_AuxPmp_Ver: server-com-spec{operation=PokePMIR_y_HT_AuxPmp_Ver, queue-length=1}, provided-interface=PokePMIR_y_HT_AuxPmp_Ver
      PokePMIR_y_LTActPump_Ver: server-com-spec{operation=PokePMIR_y_LTActPump_Ver, queue-length=1}, provided-interface=PokePMIR_y_LTActPump_Ver
      PokePMIR_y_LTPsvPump2_Ver: server-com-spec{operation=PokePMIR_y_LTPsvPump2_Ver, queue-length=1}, provided-interface=PokePMIR_y_LTPsvPump2_Ver
      PokePMIR_y_LTPsvPump_Ver: server-com-spec{operation=PokePMIR_y_LTPsvPump_Ver, queue-length=1}, provided-interface=PokePMIR_y_LTPsvPump_Ver
      PokePMIR_y_TransAuxPmp2_TAP_HW_VER: server-com-spec{operation=PokePMIR_y_TransAuxPmp2_TAP_HW_VER, queue-length=1}, provided-interface=PokePMIR_y_TransAuxPmp2_TAP_HW_VER
      PokePMIR_y_TransAuxPmp2_TAP_SW_VER: server-com-spec{operation=PokePMIR_y_TransAuxPmp2_TAP_SW_VER, queue-length=1}, provided-interface=PokePMIR_y_TransAuxPmp2_TAP_SW_VER
      PokePMIR_y_TransAuxPmp_TAP_HW_VER: server-com-spec{operation=PokePMIR_y_TransAuxPmp_TAP_HW_VER, queue-length=1}, provided-interface=PokePMIR_y_TransAuxPmp_TAP_HW_VER
      PokePMIR_y_TransAuxPmp_TAP_SW_VER: server-com-spec{operation=PokePMIR_y_TransAuxPmp_TAP_SW_VER, queue-length=1}, provided-interface=PokePMIR_y_TransAuxPmp_TAP_SW_VER
      PokePMPR_e_LTPsvPump2_PstRnSt: server-com-spec{operation=PokePMPR_e_LTPsvPump2_PstRnSt, queue-length=1}, provided-interface=PokePMPR_e_LTPsvPump2_PstRnSt
      PokePMPR_e_LTPsvPump_PstRnSt: server-com-spec{operation=PokePMPR_e_LTPsvPump_PstRnSt, queue-length=1}, provided-interface=PokePMPR_e_LTPsvPump_PstRnSt
    behavior IB_PMIR: data-type-mapping=msADTtoIDTMapping, handle-termination-and-restart=NO-SUPPORT
      timing event Event_MedTED: start-on-event=PMIR_MedTED, period=0.02
      timing event Event_MedTEH: start-on-event=PMIR_MedTEH, period=0.1
      246 x operation invoked event:
        Event_FsftPMIR_b_ECM_LTPsvPmpRq: start-on-event=FsftPMIR_b_ECM_LTPsvPmpRq, operation=FsftPMIR_b_ECM_LTPsvPmpRq.FsftPMIR_b_ECM_LTPsvPmpRq
        Event_FsftPMIR_b_FCCPmpActSpd: start-on-event=FsftPMIR_b_FCCPmpActSpd, operation=FsftPMIR_b_FCCPmpActSpd.FsftPMIR_b_FCCPmpActSpd
        Event_FsftPMIR_b_FCCPmpActTemp: start-on-event=FsftPMIR_b_FCCPmpActTemp, operation=FsftPMIR_b_FCCPmpActTemp.FsftPMIR_b_FCCPmpActTemp
        Event_FsftPMIR_b_FCCPmpActVlt: start-on-event=FsftPMIR_b_FCCPmpActVlt, operation=FsftPMIR_b_FCCPmpActVlt.FsftPMIR_b_FCCPmpActVlt
        Event_FsftPMIR_b_HTAuxPmpAirPrsntErr: start-on-event=FsftPMIR_b_HTAuxPmpAirPrsntErr, operation=FsftPMIR_b_HTAuxPmpAirPrsntErr.FsftPMIR_b_HTAuxPmpAirPrsntErr
        Event_FsftPMIR_b_HTAuxPumpDeblock: start-on-event=FsftPMIR_b_HTAuxPumpDeblock, operation=FsftPMIR_b_HTAuxPumpDeblock.FsftPMIR_b_HTAuxPumpDeblock
        Event_FsftPMIR_b_HTAuxPumpDryRun: start-on-event=FsftPMIR_b_HTAuxPumpDryRun, operation=FsftPMIR_b_HTAuxPumpDryRun.FsftPMIR_b_HTAuxPumpDryRun
        Event_FsftPMIR_b_HTAuxPumpFailsafe: start-on-event=FsftPMIR_b_HTAuxPumpFailsafe, operation=FsftPMIR_b_HTAuxPumpFailsafe.FsftPMIR_b_HTAuxPumpFailsafe
        Event_FsftPMIR_b_HTAuxPumpNodeErr: start-on-event=FsftPMIR_b_HTAuxPumpNodeErr, operation=FsftPMIR_b_HTAuxPumpNodeErr.FsftPMIR_b_HTAuxPumpNodeErr
        Event_FsftPMIR_b_HTAuxPumpOvrCrnt: start-on-event=FsftPMIR_b_HTAuxPumpOvrCrnt, operation=FsftPMIR_b_HTAuxPumpOvrCrnt.FsftPMIR_b_HTAuxPumpOvrCrnt
        Event_FsftPMIR_b_HTAuxPumpRPMAct: start-on-event=FsftPMIR_b_HTAuxPumpRPMAct, operation=FsftPMIR_b_HTAuxPumpRPMAct.FsftPMIR_b_HTAuxPumpRPMAct
        Event_FsftPMIR_b_HTAuxPumpRPMActPct: start-on-event=FsftPMIR_b_HTAuxPumpRPMActPct, operation=FsftPMIR_b_HTAuxPumpRPMActPct.FsftPMIR_b_HTAuxPumpRPMActPct
        Event_FsftPMIR_b_HTAuxPumpRPMTgt: start-on-event=FsftPMIR_b_HTAuxPumpRPMTgt, operation=FsftPMIR_b_HTAuxPumpRPMTgt.FsftPMIR_b_HTAuxPumpRPMTgt
        Event_FsftPMIR_b_HTAuxPumpRPMTgtPct: start-on-event=FsftPMIR_b_HTAuxPumpRPMTgtPct, operation=FsftPMIR_b_HTAuxPumpRPMTgtPct.FsftPMIR_b_HTAuxPumpRPMTgtPct
        Event_FsftPMIR_b_HTAuxPumpSuppVltErr: start-on-event=FsftPMIR_b_HTAuxPumpSuppVltErr, operation=FsftPMIR_b_HTAuxPumpSuppVltErr.FsftPMIR_b_HTAuxPumpSuppVltErr
        Event_FsftPMIR_b_HTAuxPump_LmpHM: start-on-event=FsftPMIR_b_HTAuxPump_LmpHM, operation=FsftPMIR_b_HTAuxPump_LmpHM.FsftPMIR_b_HTAuxPump_LmpHM
        Event_FsftPMIR_b_HT_AuxPmpCrnt: start-on-event=FsftPMIR_b_HT_AuxPmpCrnt, operation=FsftPMIR_b_HT_AuxPmpCrnt.FsftPMIR_b_HT_AuxPmpCrnt
        Event_FsftPMIR_b_HT_AuxPmpMntrRPM: start-on-event=FsftPMIR_b_HT_AuxPmpMntrRPM, operation=FsftPMIR_b_HT_AuxPmpMntrRPM.FsftPMIR_b_HT_AuxPmpMntrRPM
        Event_FsftPMIR_b_HT_AuxPmpOT: start-on-event=FsftPMIR_b_HT_AuxPmpOT, operation=FsftPMIR_b_HT_AuxPmpOT.FsftPMIR_b_HT_AuxPmpOT
        Event_FsftPMIR_b_HT_AuxPmpTemp: start-on-event=FsftPMIR_b_HT_AuxPmpTemp, operation=FsftPMIR_b_HT_AuxPmpTemp.FsftPMIR_b_HT_AuxPmpTemp
        Event_FsftPMIR_b_HT_AuxPmpVltg: start-on-event=FsftPMIR_b_HT_AuxPmpVltg, operation=FsftPMIR_b_HT_AuxPmpVltg.FsftPMIR_b_HT_AuxPmpVltg
        Event_FsftPMIR_b_HT_AuxPmp_PstRnSt: start-on-event=FsftPMIR_b_HT_AuxPmp_PstRnSt, operation=FsftPMIR_b_HT_AuxPmp_PstRnSt.FsftPMIR_b_HT_AuxPmp_PstRnSt
        Event_FsftPMIR_b_LTActPumpAirPrsntErr: start-on-event=FsftPMIR_b_LTActPumpAirPrsntErr, operation=FsftPMIR_b_LTActPumpAirPrsntErr.FsftPMIR_b_LTActPumpAirPrsntErr
        Event_FsftPMIR_b_LTActPumpCrnt: start-on-event=FsftPMIR_b_LTActPumpCrnt, operation=FsftPMIR_b_LTActPumpCrnt.FsftPMIR_b_LTActPumpCrnt
        Event_FsftPMIR_b_LTActPumpDeblock: start-on-event=FsftPMIR_b_LTActPumpDeblock, operation=FsftPMIR_b_LTActPumpDeblock.FsftPMIR_b_LTActPumpDeblock
        Event_FsftPMIR_b_LTActPumpDryRun: start-on-event=FsftPMIR_b_LTActPumpDryRun, operation=FsftPMIR_b_LTActPumpDryRun.FsftPMIR_b_LTActPumpDryRun
        Event_FsftPMIR_b_LTActPumpFailsafe: start-on-event=FsftPMIR_b_LTActPumpFailsafe, operation=FsftPMIR_b_LTActPumpFailsafe.FsftPMIR_b_LTActPumpFailsafe
        Event_FsftPMIR_b_LTActPumpLmpHM: start-on-event=FsftPMIR_b_LTActPumpLmpHM, operation=FsftPMIR_b_LTActPumpLmpHM.FsftPMIR_b_LTActPumpLmpHM
        Event_FsftPMIR_b_LTActPumpMntrRPM: start-on-event=FsftPMIR_b_LTActPumpMntrRPM, operation=FsftPMIR_b_LTActPumpMntrRPM.FsftPMIR_b_LTActPumpMntrRPM
        Event_FsftPMIR_b_LTActPumpNodeErr: start-on-event=FsftPMIR_b_LTActPumpNodeErr, operation=FsftPMIR_b_LTActPumpNodeErr.FsftPMIR_b_LTActPumpNodeErr
        Event_FsftPMIR_b_LTActPumpOvrCrnt: start-on-event=FsftPMIR_b_LTActPumpOvrCrnt, operation=FsftPMIR_b_LTActPumpOvrCrnt.FsftPMIR_b_LTActPumpOvrCrnt
        Event_FsftPMIR_b_LTActPumpPstRnSt: start-on-event=FsftPMIR_b_LTActPumpPstRnSt, operation=FsftPMIR_b_LTActPumpPstRnSt.FsftPMIR_b_LTActPumpPstRnSt
        Event_FsftPMIR_b_LTActPumpRPMAct: start-on-event=FsftPMIR_b_LTActPumpRPMAct, operation=FsftPMIR_b_LTActPumpRPMAct.FsftPMIR_b_LTActPumpRPMAct
        Event_FsftPMIR_b_LTActPumpRPMActPct: start-on-event=FsftPMIR_b_LTActPumpRPMActPct, operation=FsftPMIR_b_LTActPumpRPMActPct.FsftPMIR_b_LTActPumpRPMActPct
        Event_FsftPMIR_b_LTActPumpRPMTgt: start-on-event=FsftPMIR_b_LTActPumpRPMTgt, operation=FsftPMIR_b_LTActPumpRPMTgt.FsftPMIR_b_LTActPumpRPMTgt
        Event_FsftPMIR_b_LTActPumpRPMTgtPct: start-on-event=FsftPMIR_b_LTActPumpRPMTgtPct, operation=FsftPMIR_b_LTActPumpRPMTgtPct.FsftPMIR_b_LTActPumpRPMTgtPct
        Event_FsftPMIR_b_LTActPumpSuppVltErr: start-on-event=FsftPMIR_b_LTActPumpSuppVltErr, operation=FsftPMIR_b_LTActPumpSuppVltErr.FsftPMIR_b_LTActPumpSuppVltErr
        Event_FsftPMIR_b_LTActPumpTemp: start-on-event=FsftPMIR_b_LTActPumpTemp, operation=FsftPMIR_b_LTActPumpTemp.FsftPMIR_b_LTActPumpTemp
        Event_FsftPMIR_b_LTActPumpVlt: start-on-event=FsftPMIR_b_LTActPumpVlt, operation=FsftPMIR_b_LTActPumpVlt.FsftPMIR_b_LTActPumpVlt
        Event_FsftPMIR_b_LTPsvPmp2AirPrsntErr: start-on-event=FsftPMIR_b_LTPsvPmp2AirPrsntErr, operation=FsftPMIR_b_LTPsvPmp2AirPrsntErr.FsftPMIR_b_LTPsvPmp2AirPrsntErr
        Event_FsftPMIR_b_LTPsvPmpAirPrsntErr: start-on-event=FsftPMIR_b_LTPsvPmpAirPrsntErr, operation=FsftPMIR_b_LTPsvPmpAirPrsntErr.FsftPMIR_b_LTPsvPmpAirPrsntErr
        Event_FsftPMIR_b_LTPsvPump2Deblock: start-on-event=FsftPMIR_b_LTPsvPump2Deblock, operation=FsftPMIR_b_LTPsvPump2Deblock.FsftPMIR_b_LTPsvPump2Deblock
        Event_FsftPMIR_b_LTPsvPump2DryRun: start-on-event=FsftPMIR_b_LTPsvPump2DryRun, operation=FsftPMIR_b_LTPsvPump2DryRun.FsftPMIR_b_LTPsvPump2DryRun
        Event_FsftPMIR_b_LTPsvPump2Failsafe: start-on-event=FsftPMIR_b_LTPsvPump2Failsafe, operation=FsftPMIR_b_LTPsvPump2Failsafe.FsftPMIR_b_LTPsvPump2Failsafe
        Event_FsftPMIR_b_LTPsvPump2MntrRPM: start-on-event=FsftPMIR_b_LTPsvPump2MntrRPM, operation=FsftPMIR_b_LTPsvPump2MntrRPM.FsftPMIR_b_LTPsvPump2MntrRPM
        Event_FsftPMIR_b_LTPsvPump2NodeErr: start-on-event=FsftPMIR_b_LTPsvPump2NodeErr, operation=FsftPMIR_b_LTPsvPump2NodeErr.FsftPMIR_b_LTPsvPump2NodeErr
        Event_FsftPMIR_b_LTPsvPump2OvrCrnt: start-on-event=FsftPMIR_b_LTPsvPump2OvrCrnt, operation=FsftPMIR_b_LTPsvPump2OvrCrnt.FsftPMIR_b_LTPsvPump2OvrCrnt
        Event_FsftPMIR_b_LTPsvPump2RPMAct: start-on-event=FsftPMIR_b_LTPsvPump2RPMAct, operation=FsftPMIR_b_LTPsvPump2RPMAct.FsftPMIR_b_LTPsvPump2RPMAct
        Event_FsftPMIR_b_LTPsvPump2RPMActPct: start-on-event=FsftPMIR_b_LTPsvPump2RPMActPct, operation=FsftPMIR_b_LTPsvPump2RPMActPct.FsftPMIR_b_LTPsvPump2RPMActPct
        Event_FsftPMIR_b_LTPsvPump2RPMTgtPct: start-on-event=FsftPMIR_b_LTPsvPump2RPMTgtPct, operation=FsftPMIR_b_LTPsvPump2RPMTgtPct.FsftPMIR_b_LTPsvPump2RPMTgtPct
        Event_FsftPMIR_b_LTPsvPump2SuppVltErr: start-on-event=FsftPMIR_b_LTPsvPump2SuppVltErr, operation=FsftPMIR_b_LTPsvPump2SuppVltErr.FsftPMIR_b_LTPsvPump2SuppVltErr
        Event_FsftPMIR_b_LTPsvPump2Temp: start-on-event=FsftPMIR_b_LTPsvPump2Temp, operation=FsftPMIR_b_LTPsvPump2Temp.FsftPMIR_b_LTPsvPump2Temp
        Event_FsftPMIR_b_LTPsvPump2_LmpHM: start-on-event=FsftPMIR_b_LTPsvPump2_LmpHM, operation=FsftPMIR_b_LTPsvPump2_LmpHM.FsftPMIR_b_LTPsvPump2_LmpHM
        Event_FsftPMIR_b_LTPsvPumpDeblock: start-on-event=FsftPMIR_b_LTPsvPumpDeblock, operation=FsftPMIR_b_LTPsvPumpDeblock.FsftPMIR_b_LTPsvPumpDeblock
        Event_FsftPMIR_b_LTPsvPumpDryRun: start-on-event=FsftPMIR_b_LTPsvPumpDryRun, operation=FsftPMIR_b_LTPsvPumpDryRun.FsftPMIR_b_LTPsvPumpDryRun
        Event_FsftPMIR_b_LTPsvPumpFailsafe: start-on-event=FsftPMIR_b_LTPsvPumpFailsafe, operation=FsftPMIR_b_LTPsvPumpFailsafe.FsftPMIR_b_LTPsvPumpFailsafe
        Event_FsftPMIR_b_LTPsvPumpMntrRPM: start-on-event=FsftPMIR_b_LTPsvPumpMntrRPM, operation=FsftPMIR_b_LTPsvPumpMntrRPM.FsftPMIR_b_LTPsvPumpMntrRPM
        Event_FsftPMIR_b_LTPsvPumpNodeErr: start-on-event=FsftPMIR_b_LTPsvPumpNodeErr, operation=FsftPMIR_b_LTPsvPumpNodeErr.FsftPMIR_b_LTPsvPumpNodeErr
        Event_FsftPMIR_b_LTPsvPumpOvrCrnt: start-on-event=FsftPMIR_b_LTPsvPumpOvrCrnt, operation=FsftPMIR_b_LTPsvPumpOvrCrnt.FsftPMIR_b_LTPsvPumpOvrCrnt
        Event_FsftPMIR_b_LTPsvPumpRPMAct: start-on-event=FsftPMIR_b_LTPsvPumpRPMAct, operation=FsftPMIR_b_LTPsvPumpRPMAct.FsftPMIR_b_LTPsvPumpRPMAct
        Event_FsftPMIR_b_LTPsvPumpRPMActPct: start-on-event=FsftPMIR_b_LTPsvPumpRPMActPct, operation=FsftPMIR_b_LTPsvPumpRPMActPct.FsftPMIR_b_LTPsvPumpRPMActPct
        Event_FsftPMIR_b_LTPsvPumpRPMTgt: start-on-event=FsftPMIR_b_LTPsvPumpRPMTgt, operation=FsftPMIR_b_LTPsvPumpRPMTgt.FsftPMIR_b_LTPsvPumpRPMTgt
        Event_FsftPMIR_b_LTPsvPumpRPMTgtPct: start-on-event=FsftPMIR_b_LTPsvPumpRPMTgtPct, operation=FsftPMIR_b_LTPsvPumpRPMTgtPct.FsftPMIR_b_LTPsvPumpRPMTgtPct
        Event_FsftPMIR_b_LTPsvPumpSuppVltErr: start-on-event=FsftPMIR_b_LTPsvPumpSuppVltErr, operation=FsftPMIR_b_LTPsvPumpSuppVltErr.FsftPMIR_b_LTPsvPumpSuppVltErr
        Event_FsftPMIR_b_LTPsvPumpTemp: start-on-event=FsftPMIR_b_LTPsvPumpTemp, operation=FsftPMIR_b_LTPsvPumpTemp.FsftPMIR_b_LTPsvPumpTemp
        Event_FsftPMIR_b_LTPsvPump_LmpHM: start-on-event=FsftPMIR_b_LTPsvPump_LmpHM, operation=FsftPMIR_b_LTPsvPump_LmpHM.FsftPMIR_b_LTPsvPump_LmpHM
        Event_FsftPMIR_b_LT_ActvPmpOT: start-on-event=FsftPMIR_b_LT_ActvPmpOT, operation=FsftPMIR_b_LT_ActvPmpOT.FsftPMIR_b_LT_ActvPmpOT
        Event_FsftPMIR_b_LT_PsvPmp2Crnt: start-on-event=FsftPMIR_b_LT_PsvPmp2Crnt, operation=FsftPMIR_b_LT_PsvPmp2Crnt.FsftPMIR_b_LT_PsvPmp2Crnt
        Event_FsftPMIR_b_LT_PsvPmp2OT: start-on-event=FsftPMIR_b_LT_PsvPmp2OT, operation=FsftPMIR_b_LT_PsvPmp2OT.FsftPMIR_b_LT_PsvPmp2OT
        Event_FsftPMIR_b_LT_PsvPmp2Vltg: start-on-event=FsftPMIR_b_LT_PsvPmp2Vltg, operation=FsftPMIR_b_LT_PsvPmp2Vltg.FsftPMIR_b_LT_PsvPmp2Vltg
        Event_FsftPMIR_b_LT_PsvPmpCrnt: start-on-event=FsftPMIR_b_LT_PsvPmpCrnt, operation=FsftPMIR_b_LT_PsvPmpCrnt.FsftPMIR_b_LT_PsvPmpCrnt
        Event_FsftPMIR_b_LT_PsvPmpOT: start-on-event=FsftPMIR_b_LT_PsvPmpOT, operation=FsftPMIR_b_LT_PsvPmpOT.FsftPMIR_b_LT_PsvPmpOT
        Event_FsftPMIR_b_LT_PsvPmpVltg: start-on-event=FsftPMIR_b_LT_PsvPmpVltg, operation=FsftPMIR_b_LT_PsvPmpVltg.FsftPMIR_b_LT_PsvPmpVltg
        Event_FsftPMIR_b_TransAuxPmp2_ColdBiasSts: start-on-event=FsftPMIR_b_TransAuxPmp2_ColdBiasSts, operation=FsftPMIR_b_TransAuxPmp2_ColdBiasSts.FsftPMIR_b_TransAuxPmp2_ColdBiasSts
        Event_FsftPMIR_b_TransAuxPmp2_Crnt: start-on-event=FsftPMIR_b_TransAuxPmp2_Crnt, operation=FsftPMIR_b_TransAuxPmp2_Crnt.FsftPMIR_b_TransAuxPmp2_Crnt
        Event_FsftPMIR_b_TransAuxPmp2_CrntErr: start-on-event=FsftPMIR_b_TransAuxPmp2_CrntErr, operation=FsftPMIR_b_TransAuxPmp2_CrntErr.FsftPMIR_b_TransAuxPmp2_CrntErr
        Event_FsftPMIR_b_TransAuxPmp2_DryRun: start-on-event=FsftPMIR_b_TransAuxPmp2_DryRun, operation=FsftPMIR_b_TransAuxPmp2_DryRun.FsftPMIR_b_TransAuxPmp2_DryRun
        Event_FsftPMIR_b_TransAuxPmp2_LmpHM: start-on-event=FsftPMIR_b_TransAuxPmp2_LmpHM, operation=FsftPMIR_b_TransAuxPmp2_LmpHM.FsftPMIR_b_TransAuxPmp2_LmpHM
        Event_FsftPMIR_b_TransAuxPmp2_MntrRPM: start-on-event=FsftPMIR_b_TransAuxPmp2_MntrRPM, operation=FsftPMIR_b_TransAuxPmp2_MntrRPM.FsftPMIR_b_TransAuxPmp2_MntrRPM
        Event_FsftPMIR_b_TransAuxPmp2_OilTemp: start-on-event=FsftPMIR_b_TransAuxPmp2_OilTemp, operation=FsftPMIR_b_TransAuxPmp2_OilTemp.FsftPMIR_b_TransAuxPmp2_OilTemp
        Event_FsftPMIR_b_TransAuxPmp2_PstRnSt: start-on-event=FsftPMIR_b_TransAuxPmp2_PstRnSt, operation=FsftPMIR_b_TransAuxPmp2_PstRnSt.FsftPMIR_b_TransAuxPmp2_PstRnSt
        Event_FsftPMIR_b_TransAuxPmp2_RPMAct: start-on-event=FsftPMIR_b_TransAuxPmp2_RPMAct, operation=FsftPMIR_b_TransAuxPmp2_RPMAct.FsftPMIR_b_TransAuxPmp2_RPMAct
        Event_FsftPMIR_b_TransAuxPmp2_RPMTgt: start-on-event=FsftPMIR_b_TransAuxPmp2_RPMTgt, operation=FsftPMIR_b_TransAuxPmp2_RPMTgt.FsftPMIR_b_TransAuxPmp2_RPMTgt
        Event_FsftPMIR_b_TransAuxPmp2_RespErr: start-on-event=FsftPMIR_b_TransAuxPmp2_RespErr, operation=FsftPMIR_b_TransAuxPmp2_RespErr.FsftPMIR_b_TransAuxPmp2_RespErr
        Event_FsftPMIR_b_TransAuxPmp2_StallEvnt: start-on-event=FsftPMIR_b_TransAuxPmp2_StallEvnt, operation=FsftPMIR_b_TransAuxPmp2_StallEvnt.FsftPMIR_b_TransAuxPmp2_StallEvnt
        Event_FsftPMIR_b_TransAuxPmp2_Temp: start-on-event=FsftPMIR_b_TransAuxPmp2_Temp, operation=FsftPMIR_b_TransAuxPmp2_Temp.FsftPMIR_b_TransAuxPmp2_Temp
        Event_FsftPMIR_b_TransAuxPmp2_TempErr: start-on-event=FsftPMIR_b_TransAuxPmp2_TempErr, operation=FsftPMIR_b_TransAuxPmp2_TempErr.FsftPMIR_b_TransAuxPmp2_TempErr
        Event_FsftPMIR_b_TransAuxPmp2_Vltg: start-on-event=FsftPMIR_b_TransAuxPmp2_Vltg, operation=FsftPMIR_b_TransAuxPmp2_Vltg.FsftPMIR_b_TransAuxPmp2_Vltg
        Event_FsftPMIR_b_TransAuxPmp2_VltgErr: start-on-event=FsftPMIR_b_TransAuxPmp2_VltgErr, operation=FsftPMIR_b_TransAuxPmp2_VltgErr.FsftPMIR_b_TransAuxPmp2_VltgErr
        Event_FsftPMIR_b_TransAuxPmp_ColdBiasSts: start-on-event=FsftPMIR_b_TransAuxPmp_ColdBiasSts, operation=FsftPMIR_b_TransAuxPmp_ColdBiasSts.FsftPMIR_b_TransAuxPmp_ColdBiasSts
        Event_FsftPMIR_b_TransAuxPmp_Crnt: start-on-event=FsftPMIR_b_TransAuxPmp_Crnt, operation=FsftPMIR_b_TransAuxPmp_Crnt.FsftPMIR_b_TransAuxPmp_Crnt
        Event_FsftPMIR_b_TransAuxPmp_CrntErr: start-on-event=FsftPMIR_b_TransAuxPmp_CrntErr, operation=FsftPMIR_b_TransAuxPmp_CrntErr.FsftPMIR_b_TransAuxPmp_CrntErr
        Event_FsftPMIR_b_TransAuxPmp_DryRun: start-on-event=FsftPMIR_b_TransAuxPmp_DryRun, operation=FsftPMIR_b_TransAuxPmp_DryRun.FsftPMIR_b_TransAuxPmp_DryRun
        Event_FsftPMIR_b_TransAuxPmp_LmpHM: start-on-event=FsftPMIR_b_TransAuxPmp_LmpHM, operation=FsftPMIR_b_TransAuxPmp_LmpHM.FsftPMIR_b_TransAuxPmp_LmpHM
        Event_FsftPMIR_b_TransAuxPmp_MntrRPM: start-on-event=FsftPMIR_b_TransAuxPmp_MntrRPM, operation=FsftPMIR_b_TransAuxPmp_MntrRPM.FsftPMIR_b_TransAuxPmp_MntrRPM
        Event_FsftPMIR_b_TransAuxPmp_OilTemp: start-on-event=FsftPMIR_b_TransAuxPmp_OilTemp, operation=FsftPMIR_b_TransAuxPmp_OilTemp.FsftPMIR_b_TransAuxPmp_OilTemp
        Event_FsftPMIR_b_TransAuxPmp_PstRnSt: start-on-event=FsftPMIR_b_TransAuxPmp_PstRnSt, operation=FsftPMIR_b_TransAuxPmp_PstRnSt.FsftPMIR_b_TransAuxPmp_PstRnSt
        Event_FsftPMIR_b_TransAuxPmp_RPMAct: start-on-event=FsftPMIR_b_TransAuxPmp_RPMAct, operation=FsftPMIR_b_TransAuxPmp_RPMAct.FsftPMIR_b_TransAuxPmp_RPMAct
        Event_FsftPMIR_b_TransAuxPmp_RPMTgt: start-on-event=FsftPMIR_b_TransAuxPmp_RPMTgt, operation=FsftPMIR_b_TransAuxPmp_RPMTgt.FsftPMIR_b_TransAuxPmp_RPMTgt
        Event_FsftPMIR_b_TransAuxPmp_RespErr: start-on-event=FsftPMIR_b_TransAuxPmp_RespErr, operation=FsftPMIR_b_TransAuxPmp_RespErr.FsftPMIR_b_TransAuxPmp_RespErr
        Event_FsftPMIR_b_TransAuxPmp_StallEvnt: start-on-event=FsftPMIR_b_TransAuxPmp_StallEvnt, operation=FsftPMIR_b_TransAuxPmp_StallEvnt.FsftPMIR_b_TransAuxPmp_StallEvnt
        Event_FsftPMIR_b_TransAuxPmp_Temp: start-on-event=FsftPMIR_b_TransAuxPmp_Temp, operation=FsftPMIR_b_TransAuxPmp_Temp.FsftPMIR_b_TransAuxPmp_Temp
        Event_FsftPMIR_b_TransAuxPmp_TempErr: start-on-event=FsftPMIR_b_TransAuxPmp_TempErr, operation=FsftPMIR_b_TransAuxPmp_TempErr.FsftPMIR_b_TransAuxPmp_TempErr
        Event_FsftPMIR_b_TransAuxPmp_Vltg: start-on-event=FsftPMIR_b_TransAuxPmp_Vltg, operation=FsftPMIR_b_TransAuxPmp_Vltg.FsftPMIR_b_TransAuxPmp_Vltg
        Event_FsftPMIR_b_TransAuxPmp_VltgErr: start-on-event=FsftPMIR_b_TransAuxPmp_VltgErr, operation=FsftPMIR_b_TransAuxPmp_VltgErr.FsftPMIR_b_TransAuxPmp_VltgErr
        Event_FsftPMPR_e_LTPsvPump2_PstRnSt: start-on-event=FsftPMPR_e_LTPsvPump2_PstRnSt, operation=FsftPMPR_e_LTPsvPump2_PstRnSt.FsftPMPR_e_LTPsvPump2_PstRnSt
        Event_FsftPMPR_e_LTPsvPump_PstRnSt: start-on-event=FsftPMPR_e_LTPsvPump_PstRnSt, operation=FsftPMPR_e_LTPsvPump_PstRnSt.FsftPMPR_e_LTPsvPump_PstRnSt
        Event_PokePMIF_DVC_HT_AuxPmpCmd: start-on-event=PokePMIF_DVC_HT_AuxPmpCmd, operation=PokePMIF_DVC_HT_AuxPmpCmd.PokePMIF_DVC_HT_AuxPmpCmd
        Event_PokePMIF_DVC_LT_ActvPmpCmd: start-on-event=PokePMIF_DVC_LT_ActvPmpCmd, operation=PokePMIF_DVC_LT_ActvPmpCmd.PokePMIF_DVC_LT_ActvPmpCmd
        Event_PokePMIF_DVC_LT_PsvPmpCmd: start-on-event=PokePMIF_DVC_LT_PsvPmpCmd, operation=PokePMIF_DVC_LT_PsvPmpCmd.PokePMIF_DVC_LT_PsvPmpCmd
        Event_PokePMIR_I_FCCPmpSuppCrnt: start-on-event=PokePMIR_I_FCCPmpSuppCrnt, operation=PokePMIR_I_FCCPmpSuppCrnt.PokePMIR_I_FCCPmpSuppCrnt
        Event_PokePMIR_I_HT_AuxPmpCrnt: start-on-event=PokePMIR_I_HT_AuxPmpCrnt, operation=PokePMIR_I_HT_AuxPmpCrnt.PokePMIR_I_HT_AuxPmpCrnt
        Event_PokePMIR_I_LTActPumpCrnt: start-on-event=PokePMIR_I_LTActPumpCrnt, operation=PokePMIR_I_LTActPumpCrnt.PokePMIR_I_LTActPumpCrnt
        Event_PokePMIR_I_LT_PsvPmp2Crnt: start-on-event=PokePMIR_I_LT_PsvPmp2Crnt, operation=PokePMIR_I_LT_PsvPmp2Crnt.PokePMIR_I_LT_PsvPmp2Crnt
        Event_PokePMIR_I_LT_PsvPmpCrnt: start-on-event=PokePMIR_I_LT_PsvPmpCrnt, operation=PokePMIR_I_LT_PsvPmpCrnt.PokePMIR_I_LT_PsvPmpCrnt
        Event_PokePMIR_I_TransAuxPmp2_Crnt: start-on-event=PokePMIR_I_TransAuxPmp2_Crnt, operation=PokePMIR_I_TransAuxPmp2_Crnt.PokePMIR_I_TransAuxPmp2_Crnt
        Event_PokePMIR_I_TransAuxPmp_Crnt: start-on-event=PokePMIR_I_TransAuxPmp_Crnt, operation=PokePMIR_I_TransAuxPmp_Crnt.PokePMIR_I_TransAuxPmp_Crnt
        Event_PokePMIR_Pct_ECM_LTPsvPmpRq: start-on-event=PokePMIR_Pct_ECM_LTPsvPmpRq, operation=PokePMIR_Pct_ECM_LTPsvPmpRq.PokePMIR_Pct_ECM_LTPsvPmpRq
        Event_PokePMIR_Pct_HTAuxPumpRPMAct: start-on-event=PokePMIR_Pct_HTAuxPumpRPMAct, operation=PokePMIR_Pct_HTAuxPumpRPMAct.PokePMIR_Pct_HTAuxPumpRPMAct
        Event_PokePMIR_Pct_HTAuxPumpRPMTgt: start-on-event=PokePMIR_Pct_HTAuxPumpRPMTgt, operation=PokePMIR_Pct_HTAuxPumpRPMTgt.PokePMIR_Pct_HTAuxPumpRPMTgt
        Event_PokePMIR_Pct_LTActPumpRPMAct: start-on-event=PokePMIR_Pct_LTActPumpRPMAct, operation=PokePMIR_Pct_LTActPumpRPMAct.PokePMIR_Pct_LTActPumpRPMAct
        Event_PokePMIR_Pct_LTActPumpRPMTgt: start-on-event=PokePMIR_Pct_LTActPumpRPMTgt, operation=PokePMIR_Pct_LTActPumpRPMTgt.PokePMIR_Pct_LTActPumpRPMTgt
        Event_PokePMIR_Pct_LTPsvPump2RPMAct: start-on-event=PokePMIR_Pct_LTPsvPump2RPMAct, operation=PokePMIR_Pct_LTPsvPump2RPMAct.PokePMIR_Pct_LTPsvPump2RPMAct
        Event_PokePMIR_Pct_LTPsvPump2RPMTgt: start-on-event=PokePMIR_Pct_LTPsvPump2RPMTgt, operation=PokePMIR_Pct_LTPsvPump2RPMTgt.PokePMIR_Pct_LTPsvPump2RPMTgt
        Event_PokePMIR_Pct_LTPsvPumpRPMAct: start-on-event=PokePMIR_Pct_LTPsvPumpRPMAct, operation=PokePMIR_Pct_LTPsvPumpRPMAct.PokePMIR_Pct_LTPsvPumpRPMAct
        Event_PokePMIR_Pct_LTPsvPumpRPMTgt: start-on-event=PokePMIR_Pct_LTPsvPumpRPMTgt, operation=PokePMIR_Pct_LTPsvPumpRPMTgt.PokePMIR_Pct_LTPsvPumpRPMTgt
        Event_PokePMIR_T_FCCPmpActTemp: start-on-event=PokePMIR_T_FCCPmpActTemp, operation=PokePMIR_T_FCCPmpActTemp.PokePMIR_T_FCCPmpActTemp
        Event_PokePMIR_T_HT_AuxPmpTemp: start-on-event=PokePMIR_T_HT_AuxPmpTemp, operation=PokePMIR_T_HT_AuxPmpTemp.PokePMIR_T_HT_AuxPmpTemp
        Event_PokePMIR_T_LTActPumpTemp: start-on-event=PokePMIR_T_LTActPumpTemp, operation=PokePMIR_T_LTActPumpTemp.PokePMIR_T_LTActPumpTemp
        Event_PokePMIR_T_LTPsvPump2Temp: start-on-event=PokePMIR_T_LTPsvPump2Temp, operation=PokePMIR_T_LTPsvPump2Temp.PokePMIR_T_LTPsvPump2Temp
        Event_PokePMIR_T_LTPsvPumpTemp: start-on-event=PokePMIR_T_LTPsvPumpTemp, operation=PokePMIR_T_LTPsvPumpTemp.PokePMIR_T_LTPsvPumpTemp
        Event_PokePMIR_T_TransAuxPmp2_OilTemp: start-on-event=PokePMIR_T_TransAuxPmp2_OilTemp, operation=PokePMIR_T_TransAuxPmp2_OilTemp.PokePMIR_T_TransAuxPmp2_OilTemp
        Event_PokePMIR_T_TransAuxPmp2_Temp: start-on-event=PokePMIR_T_TransAuxPmp2_Temp, operation=PokePMIR_T_TransAuxPmp2_Temp.PokePMIR_T_TransAuxPmp2_Temp
        Event_PokePMIR_T_TransAuxPmp_OilTemp: start-on-event=PokePMIR_T_TransAuxPmp_OilTemp, operation=PokePMIR_T_TransAuxPmp_OilTemp.PokePMIR_T_TransAuxPmp_OilTemp
        Event_PokePMIR_T_TransAuxPmp_Temp: start-on-event=PokePMIR_T_TransAuxPmp_Temp, operation=PokePMIR_T_TransAuxPmp_Temp.PokePMIR_T_TransAuxPmp_Temp
        Event_PokePMIR_U_FCCPmpActVlt: start-on-event=PokePMIR_U_FCCPmpActVlt, operation=PokePMIR_U_FCCPmpActVlt.PokePMIR_U_FCCPmpActVlt
        Event_PokePMIR_U_HT_AuxPmpVltg: start-on-event=PokePMIR_U_HT_AuxPmpVltg, operation=PokePMIR_U_HT_AuxPmpVltg.PokePMIR_U_HT_AuxPmpVltg
        Event_PokePMIR_U_LTActPumpVlt: start-on-event=PokePMIR_U_LTActPumpVlt, operation=PokePMIR_U_LTActPumpVlt.PokePMIR_U_LTActPumpVlt
        Event_PokePMIR_U_LT_PsvPmp2Vltg: start-on-event=PokePMIR_U_LT_PsvPmp2Vltg, operation=PokePMIR_U_LT_PsvPmp2Vltg.PokePMIR_U_LT_PsvPmp2Vltg
        Event_PokePMIR_U_LT_PsvPmpVltg: start-on-event=PokePMIR_U_LT_PsvPmpVltg, operation=PokePMIR_U_LT_PsvPmpVltg.PokePMIR_U_LT_PsvPmpVltg
        Event_PokePMIR_U_TransAuxPmp2_Vltg: start-on-event=PokePMIR_U_TransAuxPmp2_Vltg, operation=PokePMIR_U_TransAuxPmp2_Vltg.PokePMIR_U_TransAuxPmp2_Vltg
        Event_PokePMIR_U_TransAuxPmp_Vltg: start-on-event=PokePMIR_U_TransAuxPmp_Vltg, operation=PokePMIR_U_TransAuxPmp_Vltg.PokePMIR_U_TransAuxPmp_Vltg
        Event_PokePMIR_b_FCCPmpErrLIN: start-on-event=PokePMIR_b_FCCPmpErrLIN, operation=PokePMIR_b_FCCPmpErrLIN.PokePMIR_b_FCCPmpErrLIN
        Event_PokePMIR_b_FCCPmpErrLLO: start-on-event=PokePMIR_b_FCCPmpErrLLO, operation=PokePMIR_b_FCCPmpErrLLO.PokePMIR_b_FCCPmpErrLLO
        Event_PokePMIR_b_FCCPmpErrOC: start-on-event=PokePMIR_b_FCCPmpErrOC, operation=PokePMIR_b_FCCPmpErrOC.PokePMIR_b_FCCPmpErrOC
        Event_PokePMIR_b_FCCPmpErrOT: start-on-event=PokePMIR_b_FCCPmpErrOT, operation=PokePMIR_b_FCCPmpErrOT.PokePMIR_b_FCCPmpErrOT
        Event_PokePMIR_b_FCCPmpErrOTD: start-on-event=PokePMIR_b_FCCPmpErrOTD, operation=PokePMIR_b_FCCPmpErrOTD.PokePMIR_b_FCCPmpErrOTD
        Event_PokePMIR_b_FCCPmpErrOV: start-on-event=PokePMIR_b_FCCPmpErrOV, operation=PokePMIR_b_FCCPmpErrOV.PokePMIR_b_FCCPmpErrOV
        Event_PokePMIR_b_FCCPmpErrSC: start-on-event=PokePMIR_b_FCCPmpErrSC, operation=PokePMIR_b_FCCPmpErrSC.PokePMIR_b_FCCPmpErrSC
        Event_PokePMIR_b_FCCPmpErrUV: start-on-event=PokePMIR_b_FCCPmpErrUV, operation=PokePMIR_b_FCCPmpErrUV.PokePMIR_b_FCCPmpErrUV
        Event_PokePMIR_b_FCCPmpErrVD: start-on-event=PokePMIR_b_FCCPmpErrVD, operation=PokePMIR_b_FCCPmpErrVD.PokePMIR_b_FCCPmpErrVD
        Event_PokePMIR_b_FCCPmpIntFlt: start-on-event=PokePMIR_b_FCCPmpIntFlt, operation=PokePMIR_b_FCCPmpIntFlt.PokePMIR_b_FCCPmpIntFlt
        Event_PokePMIR_b_FCCPmpStlFlt: start-on-event=PokePMIR_b_FCCPmpStlFlt, operation=PokePMIR_b_FCCPmpStlFlt.PokePMIR_b_FCCPmpStlFlt
        Event_PokePMIR_b_HTAuxPumpRespErr: start-on-event=PokePMIR_b_HTAuxPumpRespErr, operation=PokePMIR_b_HTAuxPumpRespErr.PokePMIR_b_HTAuxPumpRespErr
        Event_PokePMIR_b_LTActPumpRespErr: start-on-event=PokePMIR_b_LTActPumpRespErr, operation=PokePMIR_b_LTActPumpRespErr.PokePMIR_b_LTActPumpRespErr
        Event_PokePMIR_b_LTPsvPump2RespErr: start-on-event=PokePMIR_b_LTPsvPump2RespErr, operation=PokePMIR_b_LTPsvPump2RespErr.PokePMIR_b_LTPsvPump2RespErr
        Event_PokePMIR_b_LTPsvPumpRespErr: start-on-event=PokePMIR_b_LTPsvPumpRespErr, operation=PokePMIR_b_LTPsvPumpRespErr.PokePMIR_b_LTPsvPumpRespErr
        Event_PokePMIR_b_TransAuxPmp2_RespErr: start-on-event=PokePMIR_b_TransAuxPmp2_RespErr, operation=PokePMIR_b_TransAuxPmp2_RespErr.PokePMIR_b_TransAuxPmp2_RespErr
        Event_PokePMIR_b_TransAuxPmp_RespErr: start-on-event=PokePMIR_b_TransAuxPmp_RespErr, operation=PokePMIR_b_TransAuxPmp_RespErr.PokePMIR_b_TransAuxPmp_RespErr
        Event_PokePMIR_b_TransAuxPmp_TCM_Req: start-on-event=PokePMIR_b_TransAuxPmp_TCM_Req, operation=PokePMIR_b_TransAuxPmp_TCM_Req.PokePMIR_b_TransAuxPmp_TCM_Req
        Event_PokePMIR_e_HTAuxPmpAirPrsntErr: start-on-event=PokePMIR_e_HTAuxPmpAirPrsntErr, operation=PokePMIR_e_HTAuxPmpAirPrsntErr.PokePMIR_e_HTAuxPmpAirPrsntErr
        Event_PokePMIR_e_HTAuxPmpProdSuplr_ID: start-on-event=PokePMIR_e_HTAuxPmpProdSuplr_ID, operation=PokePMIR_e_HTAuxPmpProdSuplr_ID.PokePMIR_e_HTAuxPmpProdSuplr_ID
        Event_PokePMIR_e_HTAuxPumpDeblock: start-on-event=PokePMIR_e_HTAuxPumpDeblock, operation=PokePMIR_e_HTAuxPumpDeblock.PokePMIR_e_HTAuxPumpDeblock
        Event_PokePMIR_e_HTAuxPumpDryRun: start-on-event=PokePMIR_e_HTAuxPumpDryRun, operation=PokePMIR_e_HTAuxPumpDryRun.PokePMIR_e_HTAuxPumpDryRun
        Event_PokePMIR_e_HTAuxPumpFailsafe: start-on-event=PokePMIR_e_HTAuxPumpFailsafe, operation=PokePMIR_e_HTAuxPumpFailsafe.PokePMIR_e_HTAuxPumpFailsafe
        Event_PokePMIR_e_HTAuxPumpNodeErr: start-on-event=PokePMIR_e_HTAuxPumpNodeErr, operation=PokePMIR_e_HTAuxPumpNodeErr.PokePMIR_e_HTAuxPumpNodeErr
        Event_PokePMIR_e_HTAuxPumpOvrCrnt: start-on-event=PokePMIR_e_HTAuxPumpOvrCrnt, operation=PokePMIR_e_HTAuxPumpOvrCrnt.PokePMIR_e_HTAuxPumpOvrCrnt
        Event_PokePMIR_e_HTAuxPumpSuppVltErr: start-on-event=PokePMIR_e_HTAuxPumpSuppVltErr, operation=PokePMIR_e_HTAuxPumpSuppVltErr.PokePMIR_e_HTAuxPumpSuppVltErr
        Event_PokePMIR_e_HTAuxPump_LmpHM: start-on-event=PokePMIR_e_HTAuxPump_LmpHM, operation=PokePMIR_e_HTAuxPump_LmpHM.PokePMIR_e_HTAuxPump_LmpHM
        Event_PokePMIR_e_HT_AuxPmpMntrRPM: start-on-event=PokePMIR_e_HT_AuxPmpMntrRPM, operation=PokePMIR_e_HT_AuxPmpMntrRPM.PokePMIR_e_HT_AuxPmpMntrRPM
        Event_PokePMIR_e_HT_AuxPmpOT: start-on-event=PokePMIR_e_HT_AuxPmpOT, operation=PokePMIR_e_HT_AuxPmpOT.PokePMIR_e_HT_AuxPmpOT
        Event_PokePMIR_e_HT_AuxPmp_PstRnSt: start-on-event=PokePMIR_e_HT_AuxPmp_PstRnSt, operation=PokePMIR_e_HT_AuxPmp_PstRnSt.PokePMIR_e_HT_AuxPmp_PstRnSt
        Event_PokePMIR_e_LTActPumpAirPrsntErr: start-on-event=PokePMIR_e_LTActPumpAirPrsntErr, operation=PokePMIR_e_LTActPumpAirPrsntErr.PokePMIR_e_LTActPumpAirPrsntErr
        Event_PokePMIR_e_LTActPumpDeblock: start-on-event=PokePMIR_e_LTActPumpDeblock, operation=PokePMIR_e_LTActPumpDeblock.PokePMIR_e_LTActPumpDeblock
        Event_PokePMIR_e_LTActPumpDryRun: start-on-event=PokePMIR_e_LTActPumpDryRun, operation=PokePMIR_e_LTActPumpDryRun.PokePMIR_e_LTActPumpDryRun
        Event_PokePMIR_e_LTActPumpFailsafe: start-on-event=PokePMIR_e_LTActPumpFailsafe, operation=PokePMIR_e_LTActPumpFailsafe.PokePMIR_e_LTActPumpFailsafe
        Event_PokePMIR_e_LTActPumpLmpHM: start-on-event=PokePMIR_e_LTActPumpLmpHM, operation=PokePMIR_e_LTActPumpLmpHM.PokePMIR_e_LTActPumpLmpHM
        Event_PokePMIR_e_LTActPumpMntrRPM: start-on-event=PokePMIR_e_LTActPumpMntrRPM, operation=PokePMIR_e_LTActPumpMntrRPM.PokePMIR_e_LTActPumpMntrRPM
        Event_PokePMIR_e_LTActPumpNodeErr: start-on-event=PokePMIR_e_LTActPumpNodeErr, operation=PokePMIR_e_LTActPumpNodeErr.PokePMIR_e_LTActPumpNodeErr
        Event_PokePMIR_e_LTActPumpOvrCrnt: start-on-event=PokePMIR_e_LTActPumpOvrCrnt, operation=PokePMIR_e_LTActPumpOvrCrnt.PokePMIR_e_LTActPumpOvrCrnt
        Event_PokePMIR_e_LTActPumpProdSuplr: start-on-event=PokePMIR_e_LTActPumpProdSuplr, operation=PokePMIR_e_LTActPumpProdSuplr.PokePMIR_e_LTActPumpProdSuplr
        Event_PokePMIR_e_LTActPumpPstRnSt: start-on-event=PokePMIR_e_LTActPumpPstRnSt, operation=PokePMIR_e_LTActPumpPstRnSt.PokePMIR_e_LTActPumpPstRnSt
        Event_PokePMIR_e_LTActPumpSuppVltErr: start-on-event=PokePMIR_e_LTActPumpSuppVltErr, operation=PokePMIR_e_LTActPumpSuppVltErr.PokePMIR_e_LTActPumpSuppVltErr
        Event_PokePMIR_e_LTPsvPmp2AirPrsntErr: start-on-event=PokePMIR_e_LTPsvPmp2AirPrsntErr, operation=PokePMIR_e_LTPsvPmp2AirPrsntErr.PokePMIR_e_LTPsvPmp2AirPrsntErr
        Event_PokePMIR_e_LTPsvPmp2ProdSuplr_ID: start-on-event=PokePMIR_e_LTPsvPmp2ProdSuplr_ID, operation=PokePMIR_e_LTPsvPmp2ProdSuplr_ID.PokePMIR_e_LTPsvPmp2ProdSuplr_ID
        Event_PokePMIR_e_LTPsvPmpAirPrsntErr: start-on-event=PokePMIR_e_LTPsvPmpAirPrsntErr, operation=PokePMIR_e_LTPsvPmpAirPrsntErr.PokePMIR_e_LTPsvPmpAirPrsntErr
        Event_PokePMIR_e_LTPsvPmpProdSuplr_ID: start-on-event=PokePMIR_e_LTPsvPmpProdSuplr_ID, operation=PokePMIR_e_LTPsvPmpProdSuplr_ID.PokePMIR_e_LTPsvPmpProdSuplr_ID
        Event_PokePMIR_e_LTPsvPump2Deblock: start-on-event=PokePMIR_e_LTPsvPump2Deblock, operation=PokePMIR_e_LTPsvPump2Deblock.PokePMIR_e_LTPsvPump2Deblock
        Event_PokePMIR_e_LTPsvPump2DryRun: start-on-event=PokePMIR_e_LTPsvPump2DryRun, operation=PokePMIR_e_LTPsvPump2DryRun.PokePMIR_e_LTPsvPump2DryRun
        Event_PokePMIR_e_LTPsvPump2Failsafe: start-on-event=PokePMIR_e_LTPsvPump2Failsafe, operation=PokePMIR_e_LTPsvPump2Failsafe.PokePMIR_e_LTPsvPump2Failsafe
        Event_PokePMIR_e_LTPsvPump2MntrRPM: start-on-event=PokePMIR_e_LTPsvPump2MntrRPM, operation=PokePMIR_e_LTPsvPump2MntrRPM.PokePMIR_e_LTPsvPump2MntrRPM
        Event_PokePMIR_e_LTPsvPump2NodeErr: start-on-event=PokePMIR_e_LTPsvPump2NodeErr, operation=PokePMIR_e_LTPsvPump2NodeErr.PokePMIR_e_LTPsvPump2NodeErr
        Event_PokePMIR_e_LTPsvPump2OvrCrnt: start-on-event=PokePMIR_e_LTPsvPump2OvrCrnt, operation=PokePMIR_e_LTPsvPump2OvrCrnt.PokePMIR_e_LTPsvPump2OvrCrnt
        Event_PokePMIR_e_LTPsvPump2SuppVltErr: start-on-event=PokePMIR_e_LTPsvPump2SuppVltErr, operation=PokePMIR_e_LTPsvPump2SuppVltErr.PokePMIR_e_LTPsvPump2SuppVltErr
        Event_PokePMIR_e_LTPsvPump2_LmpHM: start-on-event=PokePMIR_e_LTPsvPump2_LmpHM, operation=PokePMIR_e_LTPsvPump2_LmpHM.PokePMIR_e_LTPsvPump2_LmpHM
        Event_PokePMIR_e_LTPsvPumpDeblock: start-on-event=PokePMIR_e_LTPsvPumpDeblock, operation=PokePMIR_e_LTPsvPumpDeblock.PokePMIR_e_LTPsvPumpDeblock
        Event_PokePMIR_e_LTPsvPumpDryRun: start-on-event=PokePMIR_e_LTPsvPumpDryRun, operation=PokePMIR_e_LTPsvPumpDryRun.PokePMIR_e_LTPsvPumpDryRun
        Event_PokePMIR_e_LTPsvPumpFailsafe: start-on-event=PokePMIR_e_LTPsvPumpFailsafe, operation=PokePMIR_e_LTPsvPumpFailsafe.PokePMIR_e_LTPsvPumpFailsafe
        Event_PokePMIR_e_LTPsvPumpMntrRPM: start-on-event=PokePMIR_e_LTPsvPumpMntrRPM, operation=PokePMIR_e_LTPsvPumpMntrRPM.PokePMIR_e_LTPsvPumpMntrRPM
        Event_PokePMIR_e_LTPsvPumpNodeErr: start-on-event=PokePMIR_e_LTPsvPumpNodeErr, operation=PokePMIR_e_LTPsvPumpNodeErr.PokePMIR_e_LTPsvPumpNodeErr
        Event_PokePMIR_e_LTPsvPumpOvrCrnt: start-on-event=PokePMIR_e_LTPsvPumpOvrCrnt, operation=PokePMIR_e_LTPsvPumpOvrCrnt.PokePMIR_e_LTPsvPumpOvrCrnt
        Event_PokePMIR_e_LTPsvPumpSuppVltErr: start-on-event=PokePMIR_e_LTPsvPumpSuppVltErr, operation=PokePMIR_e_LTPsvPumpSuppVltErr.PokePMIR_e_LTPsvPumpSuppVltErr
        Event_PokePMIR_e_LTPsvPump_LmpHM: start-on-event=PokePMIR_e_LTPsvPump_LmpHM, operation=PokePMIR_e_LTPsvPump_LmpHM.PokePMIR_e_LTPsvPump_LmpHM
        Event_PokePMIR_e_LT_ActvPmpOT: start-on-event=PokePMIR_e_LT_ActvPmpOT, operation=PokePMIR_e_LT_ActvPmpOT.PokePMIR_e_LT_ActvPmpOT
        Event_PokePMIR_e_LT_PsvPmp2OT: start-on-event=PokePMIR_e_LT_PsvPmp2OT, operation=PokePMIR_e_LT_PsvPmp2OT.PokePMIR_e_LT_PsvPmp2OT
        Event_PokePMIR_e_LT_PsvPmpOT: start-on-event=PokePMIR_e_LT_PsvPmpOT, operation=PokePMIR_e_LT_PsvPmpOT.PokePMIR_e_LT_PsvPmpOT
        Event_PokePMIR_e_TransAuxPmp2_ColdBiasSts: start-on-event=PokePMIR_e_TransAuxPmp2_ColdBiasSts, operation=PokePMIR_e_TransAuxPmp2_ColdBiasSts.PokePMIR_e_TransAuxPmp2_ColdBiasSts
        Event_PokePMIR_e_TransAuxPmp2_CrntErr: start-on-event=PokePMIR_e_TransAuxPmp2_CrntErr, operation=PokePMIR_e_TransAuxPmp2_CrntErr.PokePMIR_e_TransAuxPmp2_CrntErr
        Event_PokePMIR_e_TransAuxPmp2_DryRun: start-on-event=PokePMIR_e_TransAuxPmp2_DryRun, operation=PokePMIR_e_TransAuxPmp2_DryRun.PokePMIR_e_TransAuxPmp2_DryRun
        Event_PokePMIR_e_TransAuxPmp2_LmpHM: start-on-event=PokePMIR_e_TransAuxPmp2_LmpHM, operation=PokePMIR_e_TransAuxPmp2_LmpHM.PokePMIR_e_TransAuxPmp2_LmpHM
        Event_PokePMIR_e_TransAuxPmp2_MntrRPM: start-on-event=PokePMIR_e_TransAuxPmp2_MntrRPM, operation=PokePMIR_e_TransAuxPmp2_MntrRPM.PokePMIR_e_TransAuxPmp2_MntrRPM
        Event_PokePMIR_e_TransAuxPmp2_PstRnSt: start-on-event=PokePMIR_e_TransAuxPmp2_PstRnSt, operation=PokePMIR_e_TransAuxPmp2_PstRnSt.PokePMIR_e_TransAuxPmp2_PstRnSt
        Event_PokePMIR_e_TransAuxPmp2_StallEvnt: start-on-event=PokePMIR_e_TransAuxPmp2_StallEvnt, operation=PokePMIR_e_TransAuxPmp2_StallEvnt.PokePMIR_e_TransAuxPmp2_StallEvnt
        Event_PokePMIR_e_TransAuxPmp2_TempErr: start-on-event=PokePMIR_e_TransAuxPmp2_TempErr, operation=PokePMIR_e_TransAuxPmp2_TempErr.PokePMIR_e_TransAuxPmp2_TempErr
        Event_PokePMIR_e_TransAuxPmp2_VltgErr: start-on-event=PokePMIR_e_TransAuxPmp2_VltgErr, operation=PokePMIR_e_TransAuxPmp2_VltgErr.PokePMIR_e_TransAuxPmp2_VltgErr
        Event_PokePMIR_e_TransAuxPmp_ColdBiasSts: start-on-event=PokePMIR_e_TransAuxPmp_ColdBiasSts, operation=PokePMIR_e_TransAuxPmp_ColdBiasSts.PokePMIR_e_TransAuxPmp_ColdBiasSts
        Event_PokePMIR_e_TransAuxPmp_CrntErr: start-on-event=PokePMIR_e_TransAuxPmp_CrntErr, operation=PokePMIR_e_TransAuxPmp_CrntErr.PokePMIR_e_TransAuxPmp_CrntErr
        Event_PokePMIR_e_TransAuxPmp_DryRun: start-on-event=PokePMIR_e_TransAuxPmp_DryRun, operation=PokePMIR_e_TransAuxPmp_DryRun.PokePMIR_e_TransAuxPmp_DryRun
        Event_PokePMIR_e_TransAuxPmp_LmpHM: start-on-event=PokePMIR_e_TransAuxPmp_LmpHM, operation=PokePMIR_e_TransAuxPmp_LmpHM.PokePMIR_e_TransAuxPmp_LmpHM
        Event_PokePMIR_e_TransAuxPmp_MntrRPM: start-on-event=PokePMIR_e_TransAuxPmp_MntrRPM, operation=PokePMIR_e_TransAuxPmp_MntrRPM.PokePMIR_e_TransAuxPmp_MntrRPM
        Event_PokePMIR_e_TransAuxPmp_PstRnSt: start-on-event=PokePMIR_e_TransAuxPmp_PstRnSt, operation=PokePMIR_e_TransAuxPmp_PstRnSt.PokePMIR_e_TransAuxPmp_PstRnSt
        Event_PokePMIR_e_TransAuxPmp_StallEvnt: start-on-event=PokePMIR_e_TransAuxPmp_StallEvnt, operation=PokePMIR_e_TransAuxPmp_StallEvnt.PokePMIR_e_TransAuxPmp_StallEvnt
        Event_PokePMIR_e_TransAuxPmp_TempErr: start-on-event=PokePMIR_e_TransAuxPmp_TempErr, operation=PokePMIR_e_TransAuxPmp_TempErr.PokePMIR_e_TransAuxPmp_TempErr
        Event_PokePMIR_e_TransAuxPmp_VltgErr: start-on-event=PokePMIR_e_TransAuxPmp_VltgErr, operation=PokePMIR_e_TransAuxPmp_VltgErr.PokePMIR_e_TransAuxPmp_VltgErr
        Event_PokePMIR_n_FCCPmpActSpd: start-on-event=PokePMIR_n_FCCPmpActSpd, operation=PokePMIR_n_FCCPmpActSpd.PokePMIR_n_FCCPmpActSpd
        Event_PokePMIR_n_HTAuxPumpPmpRPMTgt: start-on-event=PokePMIR_n_HTAuxPumpPmpRPMTgt, operation=PokePMIR_n_HTAuxPumpPmpRPMTgt.PokePMIR_n_HTAuxPumpPmpRPMTgt
        Event_PokePMIR_n_HTAuxPumpRPMAct: start-on-event=PokePMIR_n_HTAuxPumpRPMAct, operation=PokePMIR_n_HTAuxPumpRPMAct.PokePMIR_n_HTAuxPumpRPMAct
        Event_PokePMIR_n_LTActPumpRPMAct: start-on-event=PokePMIR_n_LTActPumpRPMAct, operation=PokePMIR_n_LTActPumpRPMAct.PokePMIR_n_LTActPumpRPMAct
        Event_PokePMIR_n_LTActPumpRPMTgt: start-on-event=PokePMIR_n_LTActPumpRPMTgt, operation=PokePMIR_n_LTActPumpRPMTgt.PokePMIR_n_LTActPumpRPMTgt
        Event_PokePMIR_n_LTPsvPump2RPMAct: start-on-event=PokePMIR_n_LTPsvPump2RPMAct, operation=PokePMIR_n_LTPsvPump2RPMAct.PokePMIR_n_LTPsvPump2RPMAct
        Event_PokePMIR_n_LTPsvPumpRPMAct: start-on-event=PokePMIR_n_LTPsvPumpRPMAct, operation=PokePMIR_n_LTPsvPumpRPMAct.PokePMIR_n_LTPsvPumpRPMAct
        Event_PokePMIR_n_LTPsvPumpRPMTgt: start-on-event=PokePMIR_n_LTPsvPumpRPMTgt, operation=PokePMIR_n_LTPsvPumpRPMTgt.PokePMIR_n_LTPsvPumpRPMTgt
        Event_PokePMIR_n_TransAuxPmp2_RPMAct: start-on-event=PokePMIR_n_TransAuxPmp2_RPMAct, operation=PokePMIR_n_TransAuxPmp2_RPMAct.PokePMIR_n_TransAuxPmp2_RPMAct
        Event_PokePMIR_n_TransAuxPmp2_RPMTgt: start-on-event=PokePMIR_n_TransAuxPmp2_RPMTgt, operation=PokePMIR_n_TransAuxPmp2_RPMTgt.PokePMIR_n_TransAuxPmp2_RPMTgt
        Event_PokePMIR_n_TransAuxPmp_RPMAct: start-on-event=PokePMIR_n_TransAuxPmp_RPMAct, operation=PokePMIR_n_TransAuxPmp_RPMAct.PokePMIR_n_TransAuxPmp_RPMAct
        Event_PokePMIR_n_TransAuxPmp_RPMTgt: start-on-event=PokePMIR_n_TransAuxPmp_RPMTgt, operation=PokePMIR_n_TransAuxPmp_RPMTgt.PokePMIR_n_TransAuxPmp_RPMTgt
        Event_PokePMIR_y_HT_AuxPmp_Ver: start-on-event=PokePMIR_y_HT_AuxPmp_Ver, operation=PokePMIR_y_HT_AuxPmp_Ver.PokePMIR_y_HT_AuxPmp_Ver
        Event_PokePMIR_y_LTActPump_Ver: start-on-event=PokePMIR_y_LTActPump_Ver, operation=PokePMIR_y_LTActPump_Ver.PokePMIR_y_LTActPump_Ver
        Event_PokePMIR_y_LTPsvPump2_Ver: start-on-event=PokePMIR_y_LTPsvPump2_Ver, operation=PokePMIR_y_LTPsvPump2_Ver.PokePMIR_y_LTPsvPump2_Ver
        Event_PokePMIR_y_LTPsvPump_Ver: start-on-event=PokePMIR_y_LTPsvPump_Ver, operation=PokePMIR_y_LTPsvPump_Ver.PokePMIR_y_LTPsvPump_Ver
        Event_PokePMIR_y_TransAuxPmp2_TAP_HW_VER: start-on-event=PokePMIR_y_TransAuxPmp2_TAP_HW_VER, operation=PokePMIR_y_TransAuxPmp2_TAP_HW_VER.PokePMIR_y_TransAuxPmp2_TAP_HW_VER
        Event_PokePMIR_y_TransAuxPmp2_TAP_SW_VER: start-on-event=PokePMIR_y_TransAuxPmp2_TAP_SW_VER, operation=PokePMIR_y_TransAuxPmp2_TAP_SW_VER.PokePMIR_y_TransAuxPmp2_TAP_SW_VER
        Event_PokePMIR_y_TransAuxPmp_TAP_HW_VER: start-on-event=PokePMIR_y_TransAuxPmp_TAP_HW_VER, operation=PokePMIR_y_TransAuxPmp_TAP_HW_VER.PokePMIR_y_TransAuxPmp_TAP_HW_VER
        Event_PokePMIR_y_TransAuxPmp_TAP_SW_VER: start-on-event=PokePMIR_y_TransAuxPmp_TAP_SW_VER, operation=PokePMIR_y_TransAuxPmp_TAP_SW_VER.PokePMIR_y_TransAuxPmp_TAP_SW_VER
        Event_PokePMPR_e_LTPsvPump2_PstRnSt: start-on-event=PokePMPR_e_LTPsvPump2_PstRnSt, operation=PokePMPR_e_LTPsvPump2_PstRnSt.PokePMPR_e_LTPsvPump2_PstRnSt
        Event_PokePMPR_e_LTPsvPump_PstRnSt: start-on-event=PokePMPR_e_LTPsvPump_PstRnSt, operation=PokePMPR_e_LTPsvPump_PstRnSt.PokePMPR_e_LTPsvPump_PstRnSt
      init event Event_PMIR_ac_Init: start-on-event=PMIR_ac_Init
      init event Event_PwrOn: start-on-event=PMIR_PwrOn
      7 x data received event:
        Event_IOControl_IOCD016_MtrElecCoolPmpA: start-on-event=IOControl_IOCD016_MtrElecCoolPmpA, data=VeDCAB_e_IOControl_IOCD016_MtrElecCoolPmpA_Op.Value
        Event_IOControl_IOCD017_MtrElecCoolPmpB: start-on-event=IOControl_IOCD017_MtrElecCoolPmpB, data=VeDCAB_e_IOControl_IOCD017_MtrElecCoolPmpB_Op.Value
        Event_IOControl_IOCD019_BatteryCoolPump: start-on-event=IOControl_IOCD019_BatteryCoolPump, data=VeDCAB_e_IOControl_IOCD019_BatteryCoolPump_Op.Value
        Event_IOControl_IOCD00D_HigTemAuxPump: start-on-event=IOControl_IOCD00D_HigTemAuxPump, data=VeDCAB_e_IOControl_IOCD00D_HigTemAuxPump_Op.Value
        Event_IOControl_IOCD027_PowOilPumACon_Pump_Speed: start-on-event=IOControl_IOCD027_PowOilPumACon_Pump_Speed, data=VeDCAB_e_IOControl_IOCD027_PowOilPumACon_Pump_Speed_Op.Value
        Event_IOControl_IOCD028_PowOilPumBCon_Pump_Speed: start-on-event=IOControl_IOCD028_PowOilPumBCon_Pump_Speed, data=VeDCAB_e_IOControl_IOCD028_PowOilPumBCon_Pump_Speed_Op.Value
        Event_IOControl_IOCD043_PWMElectricOilPump: start-on-event=IOControl_IOCD043_PWMElectricOilPump, data=VeDCAB_e_IOControl_IOCD043_PWMElectricOilPump_Op.Value
      explicit-inter-runnable-variables:
        253 x data, all with category=VALUE, sw-calibration-access=READ-ONLY:
          TransAuxPmp_RPMAct_INIT_write_IRV: type=Float, init-value=0
          VePMIR_b_TransAuxPmp_RPMActFA_write_IRV: type=Boolean, init-value=0
          VePMIR_b_TransAuxPmp_RPMActSNA_write_IRV: type=Boolean, init-value=0
          TransAuxPmp_DryRun_INIT_write_IRV: type=TeTAPR_e_TransAuxPmp_FalseTrueSNA, init-value=CeTAPR_e_TAP_FalseTrueSNA_False
          VePMIR_b_TransAuxPmp_DryRunFA_write_IRV: type=Boolean, init-value=0
          TransAuxPmp_OilTemp_INIT_write_IRV: type=Float, init-value=0
          VePMIR_b_TransAuxPmp_OilTempFA_write_IRV: type=Boolean, init-value=0
          TransAuxPmp_Temp_INIT_write_IRV: type=Float, init-value=0
          VePMIR_b_TransAuxPmp_TempFA_write_IRV: type=Boolean, init-value=0
          TransAuxPmp_TempErr_INIT_write_IRV: type=TeTAPR_e_TransAuxPmp_TmpErr, init-value=CeTAPR_e_TmpErr_NO_FAULT
          TransAuxPmp_Vltg_INIT_write_IRV: type=Float, init-value=0
          TransAuxPmp_VltgErr_INIT_write_IRV: type=TeTAPR_e_TransAuxPmp_VltgtErr, init-value=CeTAPR_e_VltgtErr_NO_FAULT
          TransAuxPmp_Crnt_INIT_write_IRV: type=Float, init-value=0
          TransAuxPmp_CrntErr_INIT_write_IRV: type=TeTAPR_e_TransAuxPmp_CrntErr, init-value=CeTAPR_e_CrntErr_NO_FAULT
          TransAuxPmp_RPMTgt_INIT_write_IRV: type=Float, init-value=0
          TransAuxPmp_StallEvnt_INIT_write_IRV: type=TeTAPR_e_TransAuxPmp_StallEvnt, init-value=CeTAPR_e_StallEvnt_FALSE
          TransAuxPmp_LmpHM_INIT_write_IRV: type=TeTAPR_e_TransAuxPmp_FalseTrueSNA, init-value=CeTAPR_e_TAP_FalseTrueSNA_False
          TransAuxPmp_MntrRPM_INIT_write_IRV: type=TeTAPR_e_TransAuxPmp_TrueFalseSNA, init-value=CeTAPR_e_TAP_TrueFalseSNA_False
          TransAuxPmp_ColdBiasSts_INIT_write_IRV: type=TeTAPR_e_TransAuxPmp_FalseTrueSNA, init-value=CeTAPR_e_TAP_FalseTrueSNA_False
          TransAuxPmp_PstRnSt_INIT_write_IRV: type=TeTAPR_e_TransAuxPmp_PostRunCmd, init-value=CeTAPR_e_TAP_PostRunCmd_NoPostRun
          TransAuxPmp_TAP_HW_VER_INIT_write_IRV: type=UInt8, init-value=0
          TransAuxPmp_TAP_SW_VER_INIT_write_IRV: type=UInt8, init-value=0
          VePMIR_b_TransAuxPmp_RespErr_write_IRV: type=Boolean, init-value=0
          DVC_AuxPmpSpdEnbl_INIT_write_IRV: type=TeTAIR_e_IO_CntrlSt, init-value=CeTAIR_e_Return_Control_to_ECU
          DVC_AuxPmpSpdDsrd_INIT_write_IRV: type=Float, init-value=0
          TransAuxPmp_TCM_Req_INIT_write_IRV: type=Boolean, init-value=0
          TransAuxPmp2_RPMAct_INIT_write_IRV: type=Float, init-value=0
          VePMIR_b_TransAuxPmp2_RPMActFA_write_IRV: type=Boolean, init-value=0
          VePMIR_b_TransAuxPmp2_RPMActSNA_write_IRV: type=Boolean, init-value=0
          TransAuxPmp2_Temp_INIT_write_IRV: type=Float, init-value=0
          VePMIR_b_TransAuxPmp2_TempFA_write_IRV: type=Boolean, init-value=0
          TransAuxPmp2_Crnt_INIT_write_IRV: type=Float, init-value=0
          VePMIR_b_TransAuxPmp2_CrntFA_write_IRV: type=Boolean, init-value=0
          TransAuxPmp2_Vltg_INIT_write_IRV: type=Float, init-value=0
          VePMIR_b_TransAuxPmp2_VltgFA_write_IRV: type=Boolean, init-value=0
          VePMIR_b_TransAuxPmp2_RespErrFA_write_IRV: type=Boolean, init-value=0
          TransAuxPmp2_RPMTgt_INIT_write_IRV: type=Float, init-value=0
          VePMIR_b_TransAuxPmp2_RPMTgtFA_write_IRV: type=Boolean, init-value=0
          TransAuxPmp2_TAP_HW_VER_INIT_write_IRV: type=UInt8, init-value=0
          TransAuxPmp2_TAP_SW_VER_INIT_write_IRV: type=UInt8, init-value=0
          TransAuxPmp2_OilTemp_INIT_write_IRV: type=Float, init-value=0
          VePMIR_b_TransAuxPmp2_OilTempFA_write_IRV: type=Boolean, init-value=0
          TransAuxPmp2_PstRnSt_INIT_write_IRV: type=TeTAPR_e_TransAuxPmp_PostRunCmd, init-value=CeTAPR_e_TAP_PostRunCmd_NoPostRun
          VePMIR_b_TransAuxPmp2_PstRnStFA_write_IRV: type=Boolean, init-value=0
          TransAuxPmp2_LmpHM_INIT_write_IRV: type=TeTAPR_e_TransAuxPmp_FalseTrueSNA, init-value=CeTAPR_e_TAP_FalseTrueSNA_False
          VePMIR_b_TransAuxPmp2_LmpHMFA_write_IRV: type=Boolean, init-value=0
          TransAuxPmp2_DryRun_INIT_write_IRV: type=TeTAPR_e_TransAuxPmp_FalseTrueSNA, init-value=CeTAPR_e_TAP_FalseTrueSNA_False
          VePMIR_b_TransAuxPmp2_DryRunFA_write_IRV: type=Boolean, init-value=0
          TransAuxPmp2_ColdBiasSts_INIT_write_IRV: type=TeTAPR_e_TransAuxPmp_FalseTrueSNA, init-value=CeTAPR_e_TAP_FalseTrueSNA_False
          VePMIR_b_TransAuxPmp2_ColdBiasStsFA_write_IRV: type=Boolean, init-value=0
          TransAuxPmp2_MntrRPM_INIT_write_IRV: type=TeTAPR_e_TransAuxPmp_FalseTrueSNA, init-value=CeTAPR_e_TAP_FalseTrueSNA_False
          VePMIR_b_TransAuxPmp2_MntrRPMFA_write_IRV: type=Boolean, init-value=0
          TransAuxPmp2_TempErr_INIT_write_IRV: type=TeTAPR_e_TransAuxPmp_TmpErr, init-value=CeTAPR_e_TmpErr_NO_FAULT
          VePMIR_b_TransAuxPmp2_TempErrFA_write_IRV: type=Boolean, init-value=0
          TransAuxPmp2_CrntErr_INIT_write_IRV: type=TeTAPR_e_TransAuxPmp_CrntErr, init-value=CeTAPR_e_CrntErr_NO_FAULT
          VePMIR_b_TransAuxPmp2_CrntErrFA_write_IRV: type=Boolean, init-value=0
          TransAuxPmp2_StallEvnt_INIT_write_IRV: type=TeTAPR_e_TransAuxPmp_StallEvnt, init-value=CeTAPR_e_StallEvnt_FALSE
          VePMIR_b_TransAuxPmp2_StallEvntFA_write_IRV: type=Boolean, init-value=0
          TransAuxPmp2_VltgErr_INIT_write_IRV: type=TeTAPR_e_TransAuxPmp_VltgtErr, init-value=CeTAPR_e_VltgtErr_NO_FAULT
          VePMIR_b_TransAuxPmp2_VltgErrFA_write_IRV: type=Boolean, init-value=0
          DVC_AuxPmp2SpdEnbl_INIT_write_IRV: type=TeTAIR_e_IO_CntrlSt, init-value=CeTAIR_e_Return_Control_to_ECU
          DVC_AuxPmp2SpdDsrd_INIT_write_IRV: type=Float, init-value=0
          PWM_EOP_IOCtrlMode_INIT_IRV: type=TeTAIR_e_IO_CntrlSt, init-value=CeTAIR_e_Return_Control_to_ECU
          PWM_EOP_IOCtrlSpd_INIT_IRV: type=Float, init-value=0
          LT_PsvPmpOT_INIT_write_IRV: type=TePMPR_e_FTSNA, init-value=CePMPR_e_FTSNA_False
          VePMIR_b_LT_PsvPmpOTFA_write_IRV: type=Boolean, init-value=0
          LTPsvPumpRespErr_INIT_write_IRV: type=Boolean, init-value=0
          LTPsvPumpNodeErr_INIT_write_IRV: type=TePMPR_e_NodeError, init-value=CePMPR_e_NodeError_NoError
          VePMIR_b_LTPsvPumpNodeErrFA_write_IRV: type=Boolean, init-value=0
          LTPsvPumpVlt_INIT_write_IRV: type=Float, init-value=0
          VePMIR_b_LT_PsvPmpVltgFA_write_IRV: type=Boolean, init-value=0
          LTPsvPumpDryRun_INIT_write_IRV: type=TePMPR_e_FTSNA, init-value=CePMPR_e_FTSNA_False
          VePMIR_b_LTPsvPumpDryRunFA_write_IRV: type=Boolean, init-value=0
          LTPsvPmp_TgtSpd_INIT_write_IRV: type=Float, init-value=0
          VePMIR_b_LTPsvPumpRPMTgtPctFA_write_IRV: type=Boolean, init-value=0
          LTPsvPmpRPMTgt_INIT_write_IRV: type=Float, init-value=0
          VePMIR_b_LTPsvPumpRPMTgtFA_write_IRV: type=Boolean, init-value=0
          LTPsvPumpFailsafe_INIT_write_IRV: type=TePMPR_e_TFSNA, init-value=CePMPR_e_TFSNA_False
          LTPsvPumpSuppVltErr_INIT_write_IRV: type=TePMPR_e_FTSNA, init-value=CePMPR_e_FTSNA_False
          VePMIR_b_LTPsvPumpSuppVltErrFA_write_IRV: type=Boolean, init-value=0
          LTPsvPmp_ActSpd_INIT_write_IRV: type=Float, init-value=0
          VePMIR_b_LTPsvPumpRPMActPctFA_write_IRV: type=Boolean, init-value=0
          LTPsvPumpRPMAct_INIT_write_IRV: type=Float, init-value=0
          VePMIR_b_LTPsvPumpRPMActFA_write_IRV: type=Boolean, init-value=0
          VePMIR_b_LTPsvPumpRPMActPctSNA_write_IRV: type=Boolean, init-value=0
          VePMIR_b_LTPsvPumpRPMActSNA_write_IRV: type=Boolean, init-value=0
          LTPsvPumpOvrCrnt_INIT_write_IRV: type=TePMPR_e_FTSNA, init-value=CePMPR_e_FTSNA_False
          VePMIR_b_LTPsvPumpOvrCrntFA_write_IRV: type=Boolean, init-value=0
          LTPSVPumpCrnt_INIT_write_IRV: type=Float, init-value=0
          LTPsvPumpDeblock_INIT_write_IRV: type=TePMPR_e_FTSNA, init-value=CePMPR_e_FTSNA_False
          VePMIR_b_LTPsvPumpDeblockFA_write_IRV: type=Boolean, init-value=0
          LTPsvPump_LmpHM_INIT_write_IRV: type=TePMPR_e_FTSNA, init-value=CePMPR_e_FTSNA_False
          VePMIR_b_LTPsvPump_LmpHMFA_write_IRV: type=Boolean, init-value=0
          LTPsvPumpMntrRPM_INIT_write_IRV: type=TePMPR_e_TFSNA, init-value=CePMPR_e_TFSNA_False
          VePMIR_b_LTPsvPumpMntrRPMFA_write_IRV: type=Boolean, init-value=0
          LTPsvPumpTemp_INIT_write_IRV: type=Float, init-value=0
          VePMIR_b_LTPsvPumpTempFA_write_IRV: type=Boolean, init-value=0
          VePMIR_b_LTPsvPumpTempSNA_write_IRV: type=Boolean, init-value=0
          LTPsvPump_Ver_INIT_write_IRV: type=UInt8, init-value=0
          ECM_LTPsvPmpRq_INIT_write_IRV: type=Float, init-value=0
          VePMIR_b_ECM_LTPsvPmpRqFA_write_IRV: type=Boolean, init-value=0
          LTPsvPmpAirPrsntErr_INIT_write_IRV: type=TePMPR_e_FTSNA, init-value=CePMPR_e_FTSNA_False
          VePMIR_b_LTPsvPmpAirPrsntErrFA_write_IRV: type=Boolean, init-value=0
          LTPsvPmpProdSuplr_ID_INIT_write_IRV: type=UInt8, init-value=0
          LTPP_DVC_FlwRt_IO_Cntl_INIT_write_IRV: type=TeTAIR_e_IO_CntrlSt, init-value=CeTAIR_e_Return_Control_to_ECU
          LTPP_DVC_IO_Cntl_INIT_write_IRV: type=TeTAIR_e_IO_CntrlSt, init-value=CeTAIR_e_Return_Control_to_ECU
          LTPP_DVC_RPM_PEClFlwRt_INIT_write_IRV: type=Float, init-value=0
          LTPP_DVC_Pct_INIT_write_IRV: type=Float, init-value=0
          LT_PsvPmp2OT_INIT_write_IRV: type=TePMPR_e_FTSNA, init-value=CePMPR_e_FTSNA_False
          VePMIR_b_LT_PsvPmp2OTFA_write_IRV: type=Boolean, init-value=0
          LTPsvPump2RespErr_INIT_write_IRV: type=Boolean, init-value=0
          LTPsvPump2NodeErr_INIT_write_IRV: type=TePMPR_e_NodeError, init-value=CePMPR_e_NodeError_NoError
          VePMIR_b_LTPsvPump2NodeErrFA_write_IRV: type=Boolean, init-value=0
          LTPsvPump2Vlt_INIT_write_IRV: type=Float, init-value=0
          VePMIR_b_LT_PsvPmp2VltgFA_write_IRV: type=Boolean, init-value=0
          LTPsvPump2DryRun_INIT_write_IRV: type=TePMPR_e_FTSNA, init-value=CePMPR_e_FTSNA_False
          VePMIR_b_LTPsvPump2DryRunFA_write_IRV: type=Boolean, init-value=0
          LTPsvPmp2_TgtSpd_INIT_write_IRV: type=Float, init-value=0
          VePMIR_b_LTPsvPump2RPMTgtPctFA_write_IRV: type=Boolean, init-value=0
          LTPsvPump2Failsafe_INIT_write_IRV: type=TePMPR_e_TFSNA, init-value=CePMPR_e_TFSNA_False
          LTPsvPump2SuppVltErr_INIT_write_IRV: type=TePMPR_e_FTSNA, init-value=CePMPR_e_FTSNA_False
          VePMIR_b_LTPsvPump2SuppVltErrFA_write_IRV: type=Boolean, init-value=0
          LTPsvPmp2_ActSpd_INIT_write_IRV: type=Float, init-value=0
          VePMIR_b_LTPsvPump2RPMActPctFA_write_IRV: type=Boolean, init-value=0
          LTPsvPump2RPMAct_INIT_write_IRV: type=Float, init-value=0
          VePMIR_b_LTPsvPump2RPMActFA_write_IRV: type=Boolean, init-value=0
          VePMIR_b_LTPsvPump2RPMActPctSNA_write_IRV: type=Boolean, init-value=0
          VePMIR_b_LTPsvPump2RPMActSNA_write_IRV: type=Boolean, init-value=0
          LTPsvPump2OvrCrnt_INIT_write_IRV: type=TePMPR_e_FTSNA, init-value=CePMPR_e_FTSNA_False
          VePMIR_b_LTPsvPump2OvrCrntFA_write_IRV: type=Boolean, init-value=0
          LTPSVPump2Crnt_INIT_write_IRV: type=Float, init-value=0
          LTPsvPump2Deblock_INIT_write_IRV: type=TePMPR_e_FTSNA, init-value=CePMPR_e_FTSNA_False
          VePMIR_b_LTPsvPump2DeblockFA_write_IRV: type=Boolean, init-value=0
          LTPsvPump2_LmpHM_INIT_write_IRV: type=TePMPR_e_FTSNA, init-value=CePMPR_e_FTSNA_False
          VePMIR_b_LTPsvPump2_LmpHMFA_write_IRV: type=Boolean, init-value=0
          LTPsvPump2MntrRPM_INIT_write_IRV: type=TePMPR_e_TFSNA, init-value=CePMPR_e_TFSNA_False
          VePMIR_b_LTPsvPump2MntrRPMFA_write_IRV: type=Boolean, init-value=0
          LTPsvPump2Temp_INIT_write_IRV: type=Float, init-value=0
          VePMIR_b_LTPsvPump2TempFA_write_IRV: type=Boolean, init-value=0
          VePMIR_b_LTPsvPump2TempSNA_write_IRV: type=Boolean, init-value=0
          LTPsvPump2_Ver_INIT_write_IRV: type=UInt8, init-value=0
          LTPsvPump2AirPresntErr_INIT_write_IRV: type=TePMPR_e_FTSNA, init-value=CePMPR_e_FTSNA_False
          VePMIR_b_LTPsvPmp2AirPrsntErrFA_write_IRV: type=Boolean, init-value=0
          LTPsvPmp2ProdSuplrID_INIT_write_IRV: type=UInt8, init-value=0
          LTPP2_DVC_IO_Pct_INIT_write_IRV: type=TeTAIR_e_IO_CntrlSt, init-value=CeTAIR_e_Return_Control_to_ECU
          LTPP2_DVC_Pct_INIT_write_IRV: type=Float, init-value=0
          LT_ActvPmpOT_INIT_write_IRV: type=TePMPR_e_FTSNA, init-value=CePMPR_e_FTSNA_False
          VePMIR_b_LT_ActvPmpOTFA_write_IRV: type=Boolean, init-value=0
          LTActPumpRespErr_INIT_write_IRV: type=Boolean, init-value=0
          LTActPumpNodeErr_INIT_write_IRV: type=TePMPR_e_NodeError, init-value=CePMPR_e_NodeError_NoError
          LTActPumpVlt_INIT_write_IRV: type=Float, init-value=0
          VePMIR_b_LTActPumpVltFA_write_IRV: type=Boolean, init-value=0
          LTActPumpDryRun_INIT_write_IRV: type=TePMPR_e_FTSNA, init-value=CePMPR_e_FTSNA_False
          VePMIR_b_LTActPumpDryRunFA_write_IRV: type=Boolean, init-value=0
          VePMIR_b_LTActPumpDryRunSNA_write_IRV: type=Boolean, init-value=0
          LTActPumpPmpRPMTgt_INIT_write_IRV: type=Float, init-value=0
          VePMIR_b_LTActPumpRPMTgtFA_write_IRV: type=Boolean, init-value=0
          LTActPumpFailsafe_INIT_write_IRV: type=TePMPR_e_TFSNA, init-value=CePMPR_e_TFSNA_False
          LTActPumpSuppVltErr_INIT_write_IRV: type=TePMPR_e_FTSNA, init-value=CePMPR_e_FTSNA_False
          VePMIR_b_LTActPumpSuppVltErrFA_write_IRV: type=Boolean, init-value=0
          LTActPumpRPMAct_INIT_write_IRV: type=Float, init-value=0
          VePMIR_b_LTActPumpRPMActFA_write_IRV: type=Boolean, init-value=0
          LTActPumpOvrCrnt_INIT_write_IRV: type=TePMPR_e_FTSNA, init-value=CePMPR_e_FTSNA_False
          VePMIR_b_LTActPumpOvrCrntFA_write_IRV: type=Boolean, init-value=0
          LTActPumpCrnt_INIT_write_IRV: type=Float, init-value=0
          VePMIR_b_LTActPumpCrntFA_write_IRV: type=Boolean, init-value=0
          LTActPumpDeblock_INIT_write_IRV: type=TePMPR_e_FTSNA, init-value=CePMPR_e_FTSNA_False
          VePMIR_b_LTActPumpDeblockFA_write_IRV: type=Boolean, init-value=0
          LTActPumpTemp_INIT_write_IRV: type=Float, init-value=0
          VePMIR_b_LTActPumpTempFA_write_IRV: type=Boolean, init-value=0
          VePMIR_b_LTActPumpTempSNA_write_IRV: type=Boolean, init-value=0
          LTActPumpMntrRPM_INIT_write_IRV: type=TePMPR_e_FTSNA, init-value=CePMPR_e_FTSNA_False
          LTActPumpLmpHM_INIT_write_IRV: type=TePMPR_e_FTSNA, init-value=CePMPR_e_FTSNA_False
          LTActPumpPstRnSt_INIT_write_IRV: type=TeTMIR_e_ECM_LTP_FanAftRunRq, init-value=CeTMIR_e_No_AftRunRequest
          VePMIR_b_LTActPumpPstRnStFA_write_IRV: type=Boolean, init-value=0
          VePMIR_b_LTActPumpNodeErrFA_write_IRV: type=Boolean, init-value=0
          VePMIR_b_LTActPumpFailsafeFA_write_IRV: type=Boolean, init-value=0
          LTActPumpAirPrsntErr_INIT_write_IRV: type=TePMPR_e_FTSNA, init-value=CePMPR_e_FTSNA_False
          VePMIR_b_LTActPumpAirPrsntErrFA_write_IRV: type=Boolean, init-value=0
          LTActPump_Ver_INIT_write_IRV: type=UInt8, init-value=0
          LTActPumpProdSuplr_INIT_write_IRV: type=UInt8, init-value=0
          LTActPumpTgtSpd_INIT_write_IRV: type=Float, init-value=0
          VePMIR_b_LTActPumpRPMTgtPctFA_write_IRV: type=Boolean, init-value=0
          LTActPumpActSpd_INIT_write_IRV: type=Float, init-value=0
          VePMIR_b_LTActPumpRPMActPctFA_write_IRV: type=Boolean, init-value=0
          VePMIR_b_LTActPumpRPMActSNA_write_IRV: type=Boolean, init-value=0
          VePMIR_b_LTActPumpRPMActPctSNA_write_IRV: type=Boolean, init-value=0
          LTAP_DVC_FlwRt_IO_Cntl_INIT_write_IRV: type=TeTAIR_e_IO_CntrlSt, init-value=CeTAIR_e_Return_Control_to_ECU
          LTAP_DVC_RPM_BatClFlwRt_INIT_write_IRV: type=Float, init-value=0
          LTAP_DVC_IO_Pct_INIT_write_IRV: type=TeTAIR_e_IO_CntrlSt, init-value=CeTAIR_e_Return_Control_to_ECU
          LTAP_DVC_Pct_INIT_write_IRV: type=Float, init-value=0
          HTAuxPmpOT_INIT_write_IRV: type=TePMPR_e_FTSNA, init-value=CePMPR_e_FTSNA_False
          VePMIR_b_HT_AuxPmpOTFA_write_IRV: type=Boolean, init-value=0
          HTAuxPumpRespErr_INIT_write_IRV: type=Boolean, init-value=0
          HTAuxPumpNodeErr_INIT_write_IRV: type=TePMPR_e_NodeError, init-value=CePMPR_e_NodeError_NoError
          VePMIR_b_HTAuxPumpNodeErrFA_write_IRV: type=Boolean, init-value=0
          HTAuxPumpVlt_INIT_write_IRV: type=Float, init-value=0
          VePMIR_b_HT_AuxPmpVltgFA_write_IRV: type=Boolean, init-value=0
          HTAuxPumpDryRun_INIT_write_IRV: type=TePMPR_e_FTSNA, init-value=CePMPR_e_FTSNA_False
          VePMIR_b_HTAuxPumpDryRunFA_write_IRV: type=Boolean, init-value=0
          HTAuxPump_TgtSpd_INIT_write_IRV: type=Float, init-value=0
          VePMIR_b_HTAuxPumpRPMTgtPctFA_write_IRV: type=Boolean, init-value=0
          HTAuxPmpRPMTgt_INIT_write_IRV: type=Float, init-value=0
          VePMIR_b_HTAuxPumpRPMTgtFA_write_IRV: type=Boolean, init-value=0
          HTAuxPumpFailsafe_INIT_write_IRV: type=TePMPR_e_TFSNA, init-value=CePMPR_e_TFSNA_False
          HTAuxPumpSuppVltErr_INIT_write_IRV: type=TePMPR_e_FTSNA, init-value=CePMPR_e_FTSNA_False
          VePMIR_b_HTAuxPumpSuppVltErrFA_write_IRV: type=Boolean, init-value=0
          HTAuxPump_ActSpd_INIT_write_IRV: type=Float, init-value=0
          VePMIR_b_HTAuxPumpRPMActPctFA_write_IRV: type=Boolean, init-value=0
          HTAuxPumpRPMAct_INIT_write_IRV: type=Float, init-value=0
          VePMIR_b_HTAuxPumpRPMActFA_write_IRV: type=Boolean, init-value=0
          VePMIR_b_HTAuxPumpRPMActPctSNA_write_IRV: type=Boolean, init-value=0
          VePMIR_b_HTAuxPumpRPMActSNA_write_IRV: type=Boolean, init-value=0
          HTAuxPumpOvrCrnt_INIT_write_IRV: type=TePMPR_e_FTSNA, init-value=CePMPR_e_FTSNA_False
          VePMIR_b_HTAuxPumpOvrCrntFA_write_IRV: type=Boolean, init-value=0
          HTAuxPumpCrnt_INIT_write_IRV: type=Float, init-value=0
          HTAuxPumpDeblock_INIT_write_IRV: type=TePMPR_e_FTSNA, init-value=CePMPR_e_FTSNA_False
          VePMIR_b_HTAuxPumpDeblockFA_write_IRV: type=Boolean, init-value=0
          HT_AuxPmpMntrRPM_INIT_write_IRV: type=TePMPR_e_TFSNA, init-value=CePMPR_e_TFSNA_False
          VePMIR_b_HT_AuxPmpMntrRPMFA_write_IRV: type=Boolean, init-value=0
          HTAuxPump_LmpHM_INIT_write_IRV: type=TePMPR_e_FTSNA, init-value=CePMPR_e_FTSNA_False
          VePMIR_b_HTAuxPump_LmpHMFA_write_IRV: type=Boolean, init-value=0
          HT_AuxPmp_PstRnSt_INIT_write_IRV: type=TeTMIR_e_ECM_LTP_FanAftRunRq, init-value=CeTMIR_e_No_AftRunRequest
          VePMIR_b_HT_AuxPmp_PstRnStFA_write_IRV: type=Boolean, init-value=0
          HT_AuxPmpTemp_INIT_write_IRV: type=Float, init-value=0
          VePMIR_b_HT_AuxPmpTempFA_write_IRV: type=Boolean, init-value=0
          VePMIR_b_HT_AuxPmpTempSNA_write_IRV: type=Boolean, init-value=0
          HT_AuxPmp_Ver_INIT_write_IRV: type=UInt8, init-value=0
          HTAuxPumpAirPresntErr_INIT_write_IRV: type=TePMPR_e_FTSNA, init-value=CePMPR_e_FTSNA_False
          VePMIR_b_HTAuxPmpAirPrsntErrFA_write_IRV: type=Boolean, init-value=0
          HTAuxPumpProdSuplrID_INIT_write_IRV: type=UInt8, init-value=0
          HTAP_DVC_FlwRt_IO_Cntl_INIT_write_IRV: type=TeTAIR_e_IO_CntrlSt, init-value=CeTAIR_e_Return_Control_to_ECU
          HTAP_DVC_IO_Pct_INIT_write_IRV: type=TeTAIR_e_IO_CntrlSt, init-value=CeTAIR_e_Return_Control_to_ECU
          HTAP_DVC_RPM_BatClFlwRt_INIT_write_IRV: type=Float, init-value=0
          HTAP_DVC_Pct_INIT_write_IRV: type=Float, init-value=0
          FCCPmpActSpd_INIT_write_IRV: type=Float, init-value=0
          VePMIR_b_FCCPmpActSpdFA_write_IRV: type=Boolean, init-value=0
          FCCPmpSuppCrnt_INIT_write_IRV: type=Float, init-value=0
          FCCPmpActTemp_INIT_write_IRV: type=Float, init-value=0
          VePMIR_b_FCCPmpActTempFA_write_IRV: type=Boolean, init-value=0
          FCCPmpActVlt_INIT_write_IRV: type=Float, init-value=0
          VePMIR_b_FCCPmpActVltFA_write_IRV: type=Boolean, init-value=0
          FCCPmpErrSC_INIT_write_IRV: type=Boolean, init-value=0
          FCCPmpIntFlt_INIT_write_IRV: type=Boolean, init-value=0
          FCCPmpErrLIN_INIT_write_IRV: type=Boolean, init-value=0
          FCCPmpErrLLO_INIT_write_IRV: type=Boolean, init-value=0
          FCCPmpErrOC_INIT_write_IRV: type=Boolean, init-value=0
          FCCPmpErrOT_INIT_write_IRV: type=Boolean, init-value=0
          FCCPmpErrOTD_INIT_write_IRV: type=Boolean, init-value=0
          FCCPmpErrOV_INIT_write_IRV: type=Boolean, init-value=0
          FCCPmpStlFlt_INIT_write_IRV: type=Boolean, init-value=0
          FCCPmpErrUV_INIT_write_IRV: type=Boolean, init-value=0
          FCCPmpErrVD_INIT_write_IRV: type=Boolean, init-value=0
